VERSION ""

NS_ :

BS_:

BU_:
VAL_TABLE_ TM2B_FaultCode_A 57 "压缩机失速" 56 "压缩机 2 故障" 55 "压缩机故障" 51 "母线欠压" 50 "排气温度传感器故障" 49 "高压总回路接触器故障" 48 "BMS 和 TMS CAN 通讯异常" 47 "DCDC 供电故障" 42 "从机组 2 丢失" 40 "从机组 2 二级故障" 39 "从机组 2 一级故障" 38 "从机组 1 丢失" 36 "从机组 1 二级故障" 35 "从机组 1 一级故障" 34 "DCDC 故障" 33 "K2 继电器故障" 32 "高压预冲故障" 31 "PTC 通讯故障" 30 "水位低报警" 28 "ATS 水泵故障" 27 "水泵故障" 26 "压缩机 2 通讯故障" 25 "机组出水温度传感器" 24 "机组进水温度传感器" 23 "低压传感器" 22 "高压传感器" 21 "风扇故障" 19 "压缩机通讯故障" 3 "面板空调故障" 2 "PTC 故障" 1 "PTC 高级故障" 0 "无故障" ;
VAL_TABLE_ B2V_ST1_PantoChrgPosRelaySt 3 "Signal Invalid" 2 "Closed" 1 "Opened" 0 "Reserved" ;
VAL_TABLE_ B2V_ST1_PantoChrgNegRelaySt 3 "Signal Invalid" 2 "Closed" 1 "Opened" 0 "Reserved" ;
VAL_TABLE_ B2V_Fult2_ContiCurrOverLoad 3 "Level3-Most severe fault" 2 "Level 2-

More severe fault" 1 "Level 1-Light fault" 0 "Normal" ;
VAL_TABLE_ B2V_Fult2_ContiChrgCurrOverLoad 3 "Level3-Most severe fault" 2 "Level 2-

More severe fault" 1 "Level 1-Light fault" 0 "Normal" ;
VAL_TABLE_ B2V_Fult2_OverChrgCurrInTheChrg 1 "Fault" 0 "Norma" ;
VAL_TABLE_ B2V_Fult2_PanChrgNegRelOpEr 1 "Fault" 0 "Norma" ;
VAL_TABLE_ B2V_Fult2_PantoChrgNegRelWeldErr 1 "Fault" 0 "Norma" ;
VAL_TABLE_ B2V_Fult2_PantoChrgPosRelWeldErr 1 "Fault" 0 "Norma" ;
VAL_TABLE_ B2V_Fult2_DCChrgPos4RelayOpenErr 1 "Fault" 0 "Norma" ;
VAL_TABLE_ B2V_Fult2_DCChrgNeg3RelayWeldErr 1 "Fault" 0 "Norma" ;
VAL_TABLE_ B2V_Fult2_DCChrgNeg3RelayOpenErr 1 "Fault" 0 "Norma" ;
VAL_TABLE_ B2V_Fult2_DCChrgPos3RelayWeldErr 1 "Fault" 0 "Norma" ;
VAL_TABLE_ B2V_Fult2_DCChrgPos3RelayOpenErr 1 "Fault" 0 "Norma" ;
VAL_TABLE_ B2V_Fult2_DCChrgNeg2RelayWeldErr 1 "Fault" 0 "Norma" ;
VAL_TABLE_ B2V_Fult2_DCChrgNeg2RelayOpenErr 1 "Fault" 0 "Norma" ;
VAL_TABLE_ B2V_Fult2_DCChrgPos2RelayWeldErr 1 "Fault" 0 "Norma" ;
VAL_TABLE_ B2V_Fult2_DCChrgPos2RelayOpenErr 1 "Fault" 0 "Norma" ;
VAL_TABLE_ B2V_Fult2_DCChrgNeg1RelayWeldErr 1 "Fault" 0 "Norma" ;
VAL_TABLE_ B2V_Fult2_DCChrgNeg1RelayOpenErr 1 "Fault" 0 "Norma" ;
VAL_TABLE_ B2V_Fult2_DCChrgPos1RelayWeldErr 1 "Fault" 0 "Norma" ;
VAL_TABLE_ B2V_Fult2_DCChrgPos1RelayOpenErr 1 "Fault" 0 "Norma" ;
VAL_TABLE_ B2V_Fult2_MainNegRelayWeldErr 1 "Fault" 0 "Norma" ;
VAL_TABLE_ B2V_Fult2_MainNegRelayOpenErr 1 "Fault" 0 "Norma" ;
VAL_TABLE_ B2V_Fult2_MainPosRelayWeldErr 1 "Fault" 0 "Norma" ;
VAL_TABLE_ B2V_Fult2_MainPosRelayOpenErr 1 "Fault" 0 "Norma" ;
VAL_TABLE_ B2V_Fult2_InnerCommunicationErr 1 "Fault" 0 "Norma" ;
VAL_TABLE_ B2V_Fult2_AuxLoopPrechrgErr 1 "Fault" 0 "Norma" ;
VAL_TABLE_ B2V_Fult2_MainLoopPrechrgErr 1 "Fault" 0 "Norma" ;
VAL_TABLE_ B2V_Fult2_OverChrgCurrInTheDrive 3 "Level3-Most severe fault" 2 "Level 2-

More severe fault" 1 "Level 1-Light fault" 0 "Normal" ;
VAL_TABLE_ B2T_BMS_HVRelayST_A 3 "Invalid" 2 "Invalid" 1 "下高压" 0 "上高压" ;
VAL_TABLE_ B2T_ChgST_A 3 "Invalid" 2 "Invalid" 1 "Charging mode" 0 "Non-Charging mode" ;
VAL_TABLE_ B2T_RQ_HV_A 3 "Invalid" 2 "Invalid" 1 "HV Off Request" 0 "HV On Request" ;
VAL_TABLE_ B2T_RQ_SetMode_A 3 "Self-Loop Mode" 2 "Heat Mode" 1 "Cooling Mode" 0 "Shutdown Mode" ;
VAL_TABLE_ B2V_ISO_ALARM_STA 170 "无绝缘故障" 85 "有绝缘故障" ;
VAL_TABLE_ B2V_ISO_RUN_STA 170 "正常运行" 85 "绝缘功能关闭" ;
VAL_TABLE_ B2V_ISO_MSD1 1 "有故障" 0 "无故障" ;
VAL_TABLE_ B2V_ISO_MSD2 1 "有输入" 0 "无输入" ;
VAL_TABLE_ B2V_ISO_FAULT_DIR 2 "偏负母线故障" 1 "偏正母线故障" 0 "无故障" ;
VAL_TABLE_ V2B_CC2_1 1 "Connected" 0 "Not connected" ;
VAL_TABLE_ B2V_ST1_CoolingStatus 1 "cooling" 0 "not cooling" ;
VAL_TABLE_ B2V_ST1_HeatingStatus 1 "heating" 0 "not heat" ;
VAL_TABLE_ B2V_ST1_ChrgStatus 3 "Charge error" 2 "Charge Finished" 1 "Charging" 0 "not charging" ;
VAL_TABLE_ B2V_ST1_ChrgMode 3 "Other charging" 2 "AC charging" 1 "DC charging" 0 "Notcharging" ;
VAL_TABLE_ B2V_ST1_ACChrgConnectSt 1 "Connected" 0 "Not connected" ;
VAL_TABLE_ B2V_ST1_PantoChrgConnectSt 1 "Connected" 0 "Not connected" ;
VAL_TABLE_ B2V_ST1_DCChrgConnectSt 3 "Invalid" 2 "double gun connect" 1 "single gun connect" 0 "Not connected" ;
VAL_TABLE_ B2V_ST1_BMS_BalanceStatus 1 "Balancing" 0 "No Balancing" ;
VAL_TABLE_ B2V_ST1_BMS_HVStatus 3 "Fail to HV on" 2 "HV closed" 1 "Precharge or Precheck" 0 "HV open" ;
VAL_TABLE_ B2V_ST1_Aux3RelaySt 3 "Signal Invalid" 2 "Closed" 1 "Opened" 0 "Reserved" ;
VAL_TABLE_ B2V_ST1_Aux2RelaySt 3 "Signal Invalid" 2 "Closed" 1 "Opened" 0 "Reserved" ;
VAL_TABLE_ B2V_ST1_Aux1RelaySt 3 "Signal Invalid" 2 "Closed" 1 "Opened" 0 "Reserved" ;
VAL_TABLE_ B2V_ST1_ACChrgNegRelaySt 3 "Signal Invalid" 2 "Closed" 1 "Opened" 0 "Reserved" ;
VAL_TABLE_ B2V_ST1_ACChrgPosRelaySt 3 "Signal Invalid" 2 "Closed" 1 "Opened" 0 "Reserved" ;
VAL_TABLE_ B2V_ST1_PantoChrgNegRelaySt 3 "Signal Invalid" 2 "Closed" 1 "Opened" 0 "Reserved" ;
VAL_TABLE_ B2V_ST1_PantoChrgPosRelaySt 3 "Signal Invalid" 2 "Closed" 1 "Opened" 0 "Reserved" ;
VAL_TABLE_ B2V_ST1_HeatNegRelaySt 3 "Signal Invalid" 2 "Closed" 1 "Opened" 0 "Reserved" ;
VAL_TABLE_ B2V_ST1_HeatPosRelaySt 3 "Signal Invalid" 2 "Closed" 1 "Opened" 0 "Reserved" ;
VAL_TABLE_ B2V_ST1_DCChrgNeg2RelaySt 3 "Signal Invalid" 2 "Closed" 1 "Opened" 0 "Reserved" ;
VAL_TABLE_ B2V_ST1_DCChrgPos2RelaySt 3 "Signal Invalid" 2 "Closed" 1 "Opened" 0 "Reserved" ;
VAL_TABLE_ B2V_ST1_DCChrgNeg1RelaySt 3 "Signal Invalid" 2 "Closed" 1 "Opened" 0 "Reserved" ;
VAL_TABLE_ B2V_ST1_DCChrgPos1RelaySt 3 "Signal Invalid" 2 "Closed" 1 "Opened" 0 "Reserved" ;
VAL_TABLE_ B2V_ST1_PrechrgRelaySt 3 "Signal Invalid" 2 "Closed" 1 "Opened" 0 "Reserved" ;
VAL_TABLE_ B2V_ST1_MainNegRelaySt 3 "Signal Invalid" 2 "Closed" 1 "Opened" 0 "Reserved" ;
VAL_TABLE_ B2V_ST1_MainPosRelaySt 3 "Signal Invalid" 2 "Closed" 1 "Opened" 0 "Reserved" ;
VAL_TABLE_ B2V_Fult1_HVILFault 2 "Fault" 0 "Normal" ;
VAL_TABLE_ B2V_Fult1_BatSysNotMatch 2 "Fault" 0 "Normal" ;
VAL_TABLE_ B2V_Fult1_SOCChangeFast 2 "Fault" 0 "Normal" ;
VAL_TABLE_ B2V_Fult1_OverSOC 3 "Level 3 - Most severe fault" 2 "Level 2- More severe fault" 1 "Level 1-Light fault" 0 "Normal" ;
VAL_TABLE_ B2V_Fult1_OverChg 3 "Level 3 - Most severe fault" 2 "Level 2- More severe fault" 1 "Level 1-Light fault" 0 "Normal" ;
VAL_TABLE_ B2V_Fult1_UcellUniformity 3 "Level 3 - Most severe fault" 2 "Level 2- More severe fault" 1 "Level 1-Light fault" 0 "Normal" ;
VAL_TABLE_ B2V_Fult1_LowInsRes 3 "Level 3 - Most severe fault" 2 "Level 2- More severe fault" 1 "Level 1-Light fault" 0 "Normal" ;
VAL_TABLE_ B2V_Fult1_LowUcell 3 "Level 3 - Most severe fault" 2 "Level 2- More severe fault" 1 "Level 1-Light fault" 0 "Normal" ;
VAL_TABLE_ B2V_Fult1_OverUcell 3 "Level 3 - Most severe fault" 2 "Level 2- More severe fault" 1 "Level 1-Light fault" 0 "Normal" ;
VAL_TABLE_ B2V_Fult1_LowSOC 3 "Level 3 - Most severe fault" 2 "Level 2- More severe fault" 1 "Level 1-Light fault" 0 "Normal" ;
VAL_TABLE_ B2V_Fult1_PackLowHVolt 3 "Level 3 - Most severe fault" 2 "Level 2- More severe fault" 1 "Level 1-Light fault" 0 "Normal" ;
VAL_TABLE_ B2V_Fult1_PackOverHVolt 3 "Level 3 - Most severe fault" 2 "Level 2- More severe fault" 1 "Level 1-Light fault" 0 "Normal" ;
VAL_TABLE_ B2V_Fult1_OverTemp 3 "Level 3 - Most severe fault" 2 "Level 2- More severe fault" 1 "Level 1-Light fault" 0 "Normal" ;
VAL_TABLE_ B2V_Fult1_DelTemp 3 "Level 3 - Most severe fault" 2 "Level 2- More severe fault" 1 "Level 1-Light fault" 0 "Normal" ;
VAL_TABLE_ B2V_SN_FrameNo 3 "Frame4" 2 "Frame3" 1 "Frame2" 0 "Frame1" ;
VAL_TABLE_ B2V_SN_SysCode_B6_12_18_24 90 "Z" 89 "Y" 88 "X" 87 "W" 86 "V" 85 "U" 84 "T" 83 "S" 82 "R" 81 "Q" 80 "P" 79 "O" 78 "N" 77 "M" 76 "L" 75 "K" 74 "J" 73 "I" 72 "H" 71 "G" 70 "F" 69 "E" 68 "D" 67 "C" 66 "B" 65 "A" 57 "9" 56 "8" 55 "7" 54 "6" 53 "5" 52 "4" 51 "3" 50 "2" 49 "1" 48 "0" ;
VAL_TABLE_ B2V_SN_SysCode_B5_11_17_23 90 "Z" 89 "Y" 88 "X" 87 "W" 86 "V" 85 "U" 84 "T" 83 "S" 82 "R" 81 "Q" 80 "P" 79 "O" 78 "N" 77 "M" 76 "L" 75 "K" 74 "J" 73 "I" 72 "H" 71 "G" 70 "F" 69 "E" 68 "D" 67 "C" 66 "B" 65 "A" 57 "9" 56 "8" 55 "7" 54 "6" 53 "5" 52 "4" 51 "3" 50 "2" 49 "1" 48 "0" ;
VAL_TABLE_ B2V_SN_SysCode_B4_10_16_22 90 "Z" 89 "Y" 88 "X" 87 "W" 86 "V" 85 "U" 84 "T" 83 "S" 82 "R" 81 "Q" 80 "P" 79 "O" 78 "N" 77 "M" 76 "L" 75 "K" 74 "J" 73 "I" 72 "H" 71 "G" 70 "F" 69 "E" 68 "D" 67 "C" 66 "B" 65 "A" 57 "9" 56 "8" 55 "7" 54 "6" 53 "5" 52 "4" 51 "3" 50 "2" 49 "1" 48 "0" ;
VAL_TABLE_ B2V_SN_SysCode_B3_9_15_21 90 "Z" 89 "Y" 88 "X" 87 "W" 86 "V" 85 "U" 84 "T" 83 "S" 82 "R" 81 "Q" 80 "P" 79 "O" 78 "N" 77 "M" 76 "L" 75 "K" 74 "J" 73 "I" 72 "H" 71 "G" 70 "F" 69 "E" 68 "D" 67 "C" 66 "B" 65 "A" 57 "9" 56 "8" 55 "7" 54 "6" 53 "5" 52 "4" 51 "3" 50 "2" 49 "1" 48 "0" ;
VAL_TABLE_ B2V_SN_SysCode_B2_8_14_20 90 "Z" 89 "Y" 88 "X" 87 "W" 86 "V" 85 "U" 84 "T" 83 "S" 82 "R" 81 "Q" 80 "P" 79 "O" 78 "N" 77 "M" 76 "L" 75 "K" 74 "J" 73 "I" 72 "H" 71 "G" 70 "F" 69 "E" 68 "D" 67 "C" 66 "B" 65 "A" 57 "9" 56 "8" 55 "7" 54 "6" 53 "5" 52 "4" 51 "3" 50 "2" 49 "1" 48 "0" ;
VAL_TABLE_ B2V_SN_SysCode_B1_7_13_19 90 "Z" 89 "Y" 88 "X" 87 "W" 86 "V" 85 "U" 84 "T" 83 "S" 82 "R" 81 "Q" 80 "P" 79 "O" 78 "N" 77 "M" 76 "L" 75 "K" 74 "J" 73 "I" 72 "H" 71 "G" 70 "F" 69 "E" 68 "D" 67 "C" 66 "B" 65 "A" 57 "9" 56 "8" 55 "7" 54 "6" 53 "5" 52 "4" 51 "3" 50 "2" 49 "1" 48 "0" ;
VAL_TABLE_ B2V_RQ_VIN 1 "Request VIN" 0 "Not Request VIN" ;
VAL_TABLE_ V2B_CMD_MainNegRelayFlt 3 "Signal Invalid" 2 "Opened Fault" 1 "Weld" 0 "Normal" ;
VAL_TABLE_ V2B_CMD_Aux4RelayFlt 3 "Signal Invalid" 2 "Opened Fault" 1 "Weld" 0 "Normal" ;
VAL_TABLE_ V2B_CMD_Aux3RelayFlt 3 "Signal Invalid" 2 "Opened Fault" 1 "Weld" 0 "Normal" ;
VAL_TABLE_ V2B_CMD_Aux2RelayFlt 3 "Signal Invalid" 2 "Opened Fault" 1 "Weld" 0 "Normal" ;
VAL_TABLE_ V2B_CMD_Aux1RelayFlt 3 "Signal Invalid" 2 "Opened Fault" 1 "Weld" 0 "Normal" ;
VAL_TABLE_ V2B_CMD_HeatNegRelayFlt 3 "Signal Invalid" 2 "Opened Fault" 1 "Weld" 0 "Normal" ;
VAL_TABLE_ V2B_CMD_HeatPosRelayFlt 3 "Signal Invalid" 2 "Opened Fault" 1 "Weld" 0 "Normal" ;
VAL_TABLE_ V2B_CMD_ChrgPosRelayFlt 3 "Signal Invalid" 2 "Opened Fault" 1 "Weld" 0 "Normal" ;
VAL_TABLE_ V2B_CMD_MainPosRelayFlt 3 "Signal Invalid" 2 "Opened Fault" 1 "Weld" 0 "Normal" ;
VAL_TABLE_ V2B_CMD_Aux3RelayST 3 "Invalid" 2 "Closed" 1 "Opened" 0 "Reserved" ;
VAL_TABLE_ V2B_CMD_Aux2RelayST 3 "Invalid" 2 "Closed" 1 "Opened" 0 "Reserved" ;
VAL_TABLE_ V2B_CMD_Aux1RelayST 3 "Invalid" 2 "Closed" 1 "Opened" 0 "Reserved" ;
VAL_TABLE_ V2B_CMD_HeatPosRelayST 3 "Invalid" 2 "Closed" 1 "Opened" 0 "Reserved" ;
VAL_TABLE_ V2B_CMD_MainNegRelayST 3 "Invalid" 2 "Closed" 1 "Opened" 0 "Reserved" ;
VAL_TABLE_ V2B_CMD_Aux4RelayST 3 "Invalid" 2 "Closed" 1 "Opened" 0 "Reserved" ;
VAL_TABLE_ V2B_CMD_HeatNegRelayST 3 "Invalid" 2 "Closed" 1 "Opened" 0 "Reserved" ;
VAL_TABLE_ V2B_CMD_ChrgPosRelayST 3 "Invalid" 2 "Closed" 1 "Opened" 0 "Reserved" ;
VAL_TABLE_ V2B_CMD_MainPosRelayST 3 "Invalid" 2 "Closed" 1 "Opened" 0 "Reserved" ;
VAL_TABLE_ V2B_CMD_Aux3OnOff 3 "Invalid" 2 "PowerOff" 1 "PowerOn" 0 "Reserved" ;
VAL_TABLE_ V2B_CMD_Aux2OnOff 3 "Invalid" 2 "PowerOff" 1 "PowerOn" 0 "Reserved" ;
VAL_TABLE_ V2B_CMD_Aux1OnOff 3 "Invalid" 2 "PowerOff" 1 "PowerOn" 0 "Reserved" ;
VAL_TABLE_ V2B_CMD_HV_OnOff 3 "Invalid" 2 "PowerOff" 1 "PowerOn" 0 "Reserved" ;
VAL_TABLE_ V4B_MainPos 1 "Close" 0 "Open" ;
VAL_TABLE_ V3B_KeyonRun 1 "Stick" 0 "Normal" ;
VAL_TABLE_ V3B_Keyon 1 "Stick" 0 "Normal" ;
VAL_TABLE_ V2B_AUXPreRelayFlt 1 "Stick" 0 "Normal" ;
VAL_TABLE_ V2B_AUXRelayFlt 1 "Stick" 0 "Normal" ;
VAL_TABLE_ V2B_MainAuxPreRelayFlt 1 "Stick" 0 "Normal" ;
VAL_TABLE_ V2B_MainAUXRelayFlt 1 "Stick" 0 "Normal" ;
VAL_TABLE_ V2B_AUXPreRelayST 1 "Stick" 0 "Normal" ;
VAL_TABLE_ V2B_AUXRelayST 1 "Stick" 0 "Normal" ;
VAL_TABLE_ V2B_MainAuxPreRelayST 1 "Stick" 0 "Normal" ;
VAL_TABLE_ V2B_MainAuxRelayST 1 "Stick" 0 "Normal" ;
VAL_TABLE_ V2B_MainPos6RelayFlt 1 "Stick" 0 "Normal" ;
VAL_TABLE_ V2B_MainPos5RelayFlt 1 "Stick" 0 "Normal" ;
VAL_TABLE_ V2B_MainPos4RelayFlt 1 "Stick" 0 "Normal" ;
VAL_TABLE_ V2B_MainPos3RelayFlt 1 "Stick" 0 "Normal" ;
VAL_TABLE_ V2B_MainPos2RelayFlt 1 "Stick" 0 "Normal" ;
VAL_TABLE_ V2B_MainPos1RelayFlt 1 "Stick" 0 "Normal" ;
VAL_TABLE_ V2B_MainPosRelayFlt1 1 "Stick" 0 "Normal" ;
VAL_TABLE_ V2B_HeatNegRelayFlt1 1 "Stick" 0 "Normal" ;
VAL_TABLE_ V2B_HeatPosRelayFlt1 1 "Stick" 0 "Normal" ;
VAL_TABLE_ V2B_ChgNeg4RelayFlt 1 "Stick" 0 "Normal" ;
VAL_TABLE_ V2B_ChgPos4RelayFlt 1 "Stick" 0 "Normal" ;
VAL_TABLE_ V2B_ChgNeg3RelayFlt 1 "Stick" 0 "Normal" ;
VAL_TABLE_ V2B_ChgPos3RelayFlt 1 "Stick" 0 "Normal" ;
VAL_TABLE_ V2B_ChgNeg2RelayFlt 1 "Stick" 0 "Normal" ;
VAL_TABLE_ V2B_ChgPos2RelayFlt 1 "Stick" 0 "Normal" ;
VAL_TABLE_ V2B_ChgNeg1RelayFlt 1 "Stick" 0 "Normal" ;
VAL_TABLE_ V2B_ChgPos1RelayFlt 1 "Stick" 0 "Normal" ;
VAL_TABLE_ V2B_MainNegRelayFlt1 1 "Stick" 0 "Normal" ;
VAL_TABLE_ V7B_MainPos 1 "Close" 0 "Open" ;
VAL_TABLE_ V6B_MainPos 1 "Close" 0 "Open" ;
VAL_TABLE_ V5B_MainPos 1 "Close" 0 "Open" ;
VAL_TABLE_ V3B_MainPos 1 "Close" 0 "Open" ;
VAL_TABLE_ V2B_MainPos 1 "Close" 0 "Open" ;
VAL_TABLE_ V2B_HeatNegRelaySt 1 "Close" 0 "Open" ;
VAL_TABLE_ V2B_HeatPosRelaySt 1 "Close" 0 "Open" ;
VAL_TABLE_ V2B_DCChrgNeg4RelaySt 1 "Close" 0 "Open" ;
VAL_TABLE_ V2B_DCChrgPos4RelaySt 1 "Close" 0 "Open" ;
VAL_TABLE_ V2B_DCChrgNeg3RelaySt 1 "Close" 0 "Open" ;
VAL_TABLE_ V2B_DCChrgPos3RelaySt 1 "Close" 0 "Open" ;
VAL_TABLE_ V2B_DCChrgNeg2RelaySt 1 "Close" 0 "Open" ;
VAL_TABLE_ V2B_DCChrgPos2RelaySt 1 "Close" 0 "Open" ;
VAL_TABLE_ V2B_DCChrgNeg1RelaySt 1 "Close" 0 "Open" ;
VAL_TABLE_ V2B_DCChrgPos1RelaySt 1 "Close" 0 "Open" ;
VAL_TABLE_ V2B_MainNegRelaySt 1 "Close" 0 "Open" ;
VAL_TABLE_ TM2B_FaultLevel_A 0 "Normal" 3 "Level 3 Fault" 2 "Level 2 Fault" 1 "Level 1 Fault" ;
VAL_TABLE_ T2B_TMS_HVRelayST_A 1 "Close" 0 "Open" ;
VAL_TABLE_ T2B_WorkStatus_A 3 "Self-Loop Mode" 2 "Heat

Mode" 1 "Cooling Mode" 0 "Shutdown Mode" ;
VAL_TABLE_ B2V_InsForbidCMD 1 "allow

insulation detection" 0 "forbid insulation detection" ;
VAL_TABLE_ B2V_MainPosRelayCMD 1 "require contactor

close" 0 "require contactor open" ;
VAL_TABLE_ B2V_HeatNegRelayCMD 1 "require contactor

close" 0 "require contactor open" ;
VAL_TABLE_ B2V_HeatPosRelayCMD 1 "require contactor

close" 0 "require contactor open" ;
VAL_TABLE_ B2VChrgRelay3CMD 1 "require contactor

close" 0 "require contactor open" ;
VAL_TABLE_ B2VChrgRelay2CMD 1 "require contactor

close" 0 "require contactor open" ;
VAL_TABLE_ B2VChrgRelay1CMD 1 "require contactor

close" 0 "require contactor open" ;
VAL_TABLE_ B2V_ChrgRelayCMD 1 "require contactor

close" 0 "require contactor open" ;
VAL_TABLE_ B2V_BI1_BattManufacture 7 "Others" 6 "SUNWODA" 5 "GUOXUAN HIGH_TECH" 4 "LG" 3 "SAMSUN" 2 "MGL" 1 "Li Shen" 0 "CATL" ;
VAL_TABLE_ B2V_BI1_BattType 14 "其他车载储能装置" 13 "燃

料电池 Fuel battery" 12 "Reserved" 11 "Reserved" 10 "Reserved" 9 "Reserved" 8 "超级电容Super-capaciyor" 7 "钛酸锂电池" 6 "聚合物锂离子电池" 5 "三元材料电池 NCM" 4 "钴酸锂电池" 3 "锰酸锂电池" 2 "磷酸铁锂电池LEP" 1 "镍氢电池NIMH Battery" 0 "铅酸电池Lead-acid battery" ;
VAL_TABLE_ B2V_S_ChargeControl 2 "Fault, Stop to charge" 1 "Normal Stop to charge" 0 "Start to charge" ;
VAL_TABLE_ B2V_ST6_MinUcell_CSCNo 18 "CSC18" 17 "CSC17" 16 "CSC16" 15 "CSC15" 14 "CSC14" 13 "CSC13" 12 "CSC12" 11 "CSC11" 10 "CSC10" 9 "CSC9" 8 "CSC8" 7 "CSC7" 6 "CSC6" 5 "CSC5" 4 "CSC4" 3 "CSC3" 2 "CSC2" 1 "CSC1" ;
VAL_TABLE_ B2V_ST6_MaxUcell_CSCNo 18 "CSC18" 17 "CSC17" 16 "CSC16" 15 "CSC15" 14 "CSC14" 13 "CSC13" 12 "CSC12" 11 "CSC11" 10 "CSC10" 9 "CSC9" 8 "CSC8" 7 "CSC7" 6 "CSC6" 5 "CSC5" 4 "CSC4" 3 "CSC3" 2 "CSC2" 1 "CSC1" ;
VAL_TABLE_ B2V_ST4_MinTemp_CSCNo 18 "CSC18" 17 "CSC17" 16 "CSC16" 15 "CSC15" 14 "CSC14" 13 "CSC13" 12 "CSC12" 11 "CSC11" 10 "CSC10" 9 "CSC9" 8 "CSC8" 7 "CSC7" 6 "CSC6" 5 "CSC5" 4 "CSC4" 3 "CSC3" 2 "CSC2" 1 "CSC1" ;
VAL_TABLE_ B2V_ST4_MaxTemp_CSCNo 18 "CSC18" 17 "CSC17" 16 "CSC16" 15 "CSC15" 14 "CSC14" 13 "CSC13" 12 "CSC12" 11 "CSC11" 10 "CSC10" 9 "CSC9" 8 "CSC8" 7 "CSC7" 6 "CSC6" 5 "CSC5" 4 "CSC4" 3 "CSC3" 2 "CSC2" 1 "CSC1" ;
VAL_TABLE_ B2V_ST2_RqHVPoerOff 3 "Signal Invalid" 2 "not

require power off" 1 "require power off" 0 "Signal Invalid" ;
VAL_TABLE_ B2V_ST2_FaultLevel 3 "Level3-Most severe fault" 2 "Level 2-

More severe fault" 1 "Level 1-Light fault" 0 "Normal" ;
VAL_TABLE_ B2V_Fult2_DCChrgPos1RelayWeldErr 1 "Fault" 0 "Norma" ;
VAL_TABLE_ B2V_Fult2_ACANLost 1 "Fault" 0 "Normal" ;
VAL_TABLE_ B2V_Fult2_ContiDischrgCurrLoad 3 "Level3-Most severe fault" 2 "Level 2-

More severe fault" 1 "Level 1-Light fault" 0 "Normal" ;
VAL_TABLE_ B2V_Fult2_ContiChrgCurrOverLoad 3 "Level3-Most severe fault" 2 "Level 2-

More severe fault" 1 "Level 1-Light fault" 0 "Normal" ;
VAL_TABLE_ B2V_Fult2_ChrgNTCTempOver 3 "Level3-Most severe fault" 2 "Level 2-

More severe fault" 1 "Level 1-Light fault" 0 "Normal" ;
VAL_TABLE_ B2V_Fult2_OverChrgCurrInTheDrive 3 "Level3-Most severe fault" 2 "Level 2-

More severe fault" 1 "Level 1-Light fault" 0 "Normal" ;
VAL_TABLE_ B2V_Fult2_OverDischrgCurr 3 "Level3-Most severe fault" 2 "Level 2-

More severe fault" 1 "Level 1-Light fault" 0 "Normal" ;
VAL_TABLE_ B2V_Fult2_SOCDifferErr 1 "Fault" 0 "Norma" ;
VAL_TABLE_ B2V_Fult2_FireDetectorErr 1 "Fault" 0 "Norma" ;
VAL_TABLE_ B2V_Fult2_ELockErr 1 "Fault" 0 "Norma" ;
VAL_TABLE_ B2V_Fult2_ChrgNTCErr 1 "Fault" 0 "Norma" ;
VAL_TABLE_ B2V_Fult2_OverChrgCurrInTheChrg 1 "Fault" 0 "Norma" ;
VAL_TABLE_ B2V_Fult2_OverDischrCurrWhCh 1 "Fault" 0 "Norma" ;
VAL_TABLE_ B2V_Fult2_ChrgConnectErr 1 "Fault" 0 "Norma" ;
VAL_TABLE_ B2V_Fult2_PantoChrgNegRelWeldEr 1 "Fault" 0 "Norma" ;
VAL_TABLE_ B2V_Fult2_PantoChrgNegRelOpenEr 1 "Fault" 0 "Norma" ;
VAL_TABLE_ B2V_Fult2_PantoChrgPosRelWeldErr 1 "Fault" 0 "Norma" ;
VAL_TABLE_ B2V_Fult2_DCChrgPos4RelayOpenErr 1 "Fault" 0 "Norma" ;
VAL_TABLE_ B2V_Fult2_DCChrgNeg3RelayWeldErr 1 "Fault" 0 "Norma" ;
VAL_TABLE_ B2V_Fult2_DCChrgNeg3RelayOpenErr 1 "Fault" 0 "Norma" ;
VAL_TABLE_ B2V_Fult2_DCChrgPos3RelayWeldErr 1 "Fault" 0 "Norma" ;
VAL_TABLE_ B2V_Fult2_DCChrgPos3RelayOpenErr 1 "Fault" 0 "Norma" ;
VAL_TABLE_ B2V_Fult2_DCChrgNeg2RelayWeldErr 1 "Fault" 0 "Norma" ;
VAL_TABLE_ B2V_Fult2_DCChrgNeg2RelayOpenErr 1 "Fault" 0 "Norma" ;
VAL_TABLE_ B2V_Fult2_DCChrgPos2RelayWeldErr 1 "Fault" 0 "Norma" ;
VAL_TABLE_ B2V_Fult2_DCChrgPos2RelayOpenErr 1 "Fault" 0 "Norma" ;
VAL_TABLE_ B2V_Fult2_DCChrgNeg1RelayWeldErr 1 "Fault" 0 "Norma" ;
VAL_TABLE_ B2V_Fult2_DCChrgNeg1RelayOpenErr 1 "Fault" 0 "Norma" ;
VAL_TABLE_ B2V_Fult2_DCChrgPos1RelayOpenErr 1 "Fault" 0 "Norma" ;
VAL_TABLE_ B2V_Fult2_MainNegRelayWeldErr 1 "Fault" 0 "Norma" ;
VAL_TABLE_ B2V_Fult2_MainNegRelayOpenErr 1 "Fault" 0 "Norma" ;
VAL_TABLE_ B2V_Fult2_MainPosRelayWeldErr 1 "Fault" 0 "Norma" ;
VAL_TABLE_ B2V_Fult2_MainPosRelayOpenErr 1 "Fault" 0 "Norma" ;
VAL_TABLE_ B2V_Fult2_HeatRelayWeldErr 1 "Fault" 0 "Norma" ;
VAL_TABLE_ B2V_Fult2_HeatRelayOpenErr 1 "Fault" 0 "Norma" ;
VAL_TABLE_ B2V_Fult2_BranchBreakErr 1 "Fault" 0 "Norma" ;
VAL_TABLE_ B2V_Fult2_InnerCommunicationErr 1 "Fault" 0 "Norma" ;
VAL_TABLE_ B2V_Fult2_DCDCErr 1 "Fault" 0 "Norma" ;
VAL_TABLE_ B2V_Fult2_ChrgInsLowErr 1 "Fault" 0 "Norma" ;
VAL_TABLE_ B2V_Fult2_AuxLoopPrechrgErr 1 "Fault" 0 "Norma" ;
VAL_TABLE_ B2V_Fult2_MainLoopPrechrgErr 1 "Fault" 0 "Norma" ;
VAL_TABLE_ B2V_Fult2_PackSelfProtect 1 "Fault" 0 "Norma" ;
VAL_TABLE_ B2V_Fult2_HeatungFilmErr 1 "Fault" 0 "Norma" ;
VAL_TABLE_ B2V_Fult2_TMSErr 1 "Fault" 0 "Norma" ;
VAL_TABLE_ B2V_Fult2_PowerSupplyErr 1 "Fault" 0 "Norma" ;
VAL_TABLE_ B2V_Fult2_CurrSensorErr 1 "Fault" 0 "Norma" ;
VAL_TABLE_ B2V_Fult2_PackFireWarning 1 "Fault" 0 "Norma" ;
VAL_TABLE_ B2V_Fult2_CellLowTemp 1 "Fault" 0 "Norma" ;
VAL_TABLE_ B2V_Fult2_CellOverDischrg 1 "Fault" 0 "Norma" ;
VAL_TABLE_ B2V_BI1_BattManufacture 7 "Others" 6 "SUNWODA" 5 "GUOXUAN HIGH_TECH" 4 "LG" 3 "SAMSUN" 2 "MGL" 1 "Li Shen" 0 "CATL" ;
VAL_TABLE_ B2V_BI1_CoolType 3 "Water cooling" 2 "Fan cooling" 1 "Natural cooling" 0 "Other cooling mode" ;
VAL_TABLE_ B2V_BI1_BattType 14 "其他车载储能装置" 13 "燃

料电池 Fuel battery" 12 "Reserved" 11 "Reserved" 10 "Reserved" 9 "Reserved" 8 "超级电容Super-capaciyor" 7 "钛酸锂电池" 6 "聚合物锂离子电池" 5 "三元材料电池 NCM" 4 "钴酸锂电池" 3 "锰酸锂电池" 2 "磷酸铁锂电池LEP" 1 "镍氢电池NIMH Battery" 0 "铅酸电池Lead-acid battery" ;
VAL_TABLE_ V2B_VIN_B7_14 90 "Z" 89 "Y" 88 "X" 87 "W" 86 "V" 85 "U" 84 "T" 83 "S" 82 "R" 81 "Q" 80 "P" 79 "O" 78 "N" 77 "M" 76 "L" 75 "K" 74 "J" 73 "I" 72 "H" 71 "G" 70 "F" 69 "E" 68 "D" 67 "C" 66 "B" 65 "A" 57 "9" 56 "8" 55 "7" 54 "6" 53 "5" 52 "4" 51 "3" 50 "2" 49 "1" 48 "0" ;
VAL_TABLE_ V2B_VIN_B6_13 90 "Z" 89 "Y" 88 "X" 87 "W" 86 "V" 85 "U" 84 "T" 83 "S" 82 "R" 81 "Q" 80 "P" 79 "O" 78 "N" 77 "M" 76 "L" 75 "K" 74 "J" 73 "I" 72 "H" 71 "G" 70 "F" 69 "E" 68 "D" 67 "C" 66 "B" 65 "A" 57 "9" 56 "8" 55 "7" 54 "6" 53 "5" 52 "4" 51 "3" 50 "2" 49 "1" 48 "0" ;
VAL_TABLE_ V2B_VIN_B5_12 90 "Z" 89 "Y" 88 "X" 87 "W" 86 "V" 85 "U" 84 "T" 83 "S" 82 "R" 81 "Q" 80 "P" 79 "O" 78 "N" 77 "M" 76 "L" 75 "K" 74 "J" 73 "I" 72 "H" 71 "G" 70 "F" 69 "E" 68 "D" 67 "C" 66 "B" 65 "A" 57 "9" 56 "8" 55 "7" 54 "6" 53 "5" 52 "4" 51 "3" 50 "2" 49 "1" 48 "0" ;
VAL_TABLE_ V2B_VIN_B4_11 90 "Z" 89 "Y" 88 "X" 87 "W" 86 "V" 85 "U" 84 "T" 83 "S" 82 "R" 81 "Q" 80 "P" 79 "O" 78 "N" 77 "M" 76 "L" 75 "K" 74 "J" 73 "I" 72 "H" 71 "G" 70 "F" 69 "E" 68 "D" 67 "C" 66 "B" 65 "A" 57 "9" 56 "8" 55 "7" 54 "6" 53 "5" 52 "4" 51 "3" 50 "2" 49 "1" 48 "0" ;
VAL_TABLE_ V2B_VIN_B3_10_17 90 "Z" 89 "Y" 88 "X" 87 "W" 86 "V" 85 "U" 84 "T" 83 "S" 82 "R" 81 "Q" 80 "P" 79 "O" 78 "N" 77 "M" 76 "L" 75 "K" 74 "J" 73 "I" 72 "H" 71 "G" 70 "F" 69 "E" 68 "D" 67 "C" 66 "B" 65 "A" 57 "9" 56 "8" 55 "7" 54 "6" 53 "5" 52 "4" 51 "3" 50 "2" 49 "1" 48 "0" ;
VAL_TABLE_ V2B_VIN_B2_9_16 90 "Z" 89 "Y" 88 "X" 87 "W" 86 "V" 85 "U" 84 "T" 83 "S" 82 "R" 81 "Q" 80 "P" 79 "O" 78 "N" 77 "M" 76 "L" 75 "K" 74 "J" 73 "I" 72 "H" 71 "G" 70 "F" 69 "E" 68 "D" 67 "C" 66 "B" 65 "A" 57 "9" 56 "8" 55 "7" 54 "6" 53 "5" 52 "4" 51 "3" 50 "2" 49 "1" 48 "0" ;
VAL_TABLE_ V2B_VIN_B1_8_15 90 "Z" 89 "Y" 88 "X" 87 "W" 86 "V" 85 "U" 84 "T" 83 "S" 82 "R" 81 "Q" 80 "P" 79 "O" 78 "N" 77 "M" 76 "L" 75 "K" 74 "J" 73 "I" 72 "H" 71 "G" 70 "F" 69 "E" 68 "D" 67 "C" 66 "B" 65 "A" 57 "9" 56 "8" 55 "7" 54 "6" 53 "5" 52 "4" 51 "3" 50 "2" 49 "1" 48 "0" ;
VAL_TABLE_ ISO_FaultLevel 3 "Level3-Most severe fault" 2 "Level 2-

More severe fault" 1 "Level 1-Light fault" 0 "Normal" ;
VAL_TABLE_ ISOWorkStatus 3 "equipment failure" 2 "stop work" 1 "working" 0 "Selfcheck" ;

BO_ 468 PDI1: 1 Vector__XXX
 SG_ X03 : 2|1@1- (1,0) [0|0] "" Vector__XXX
 SG_ X02 : 1|1@1- (1,0) [0|0] "" Vector__XXX

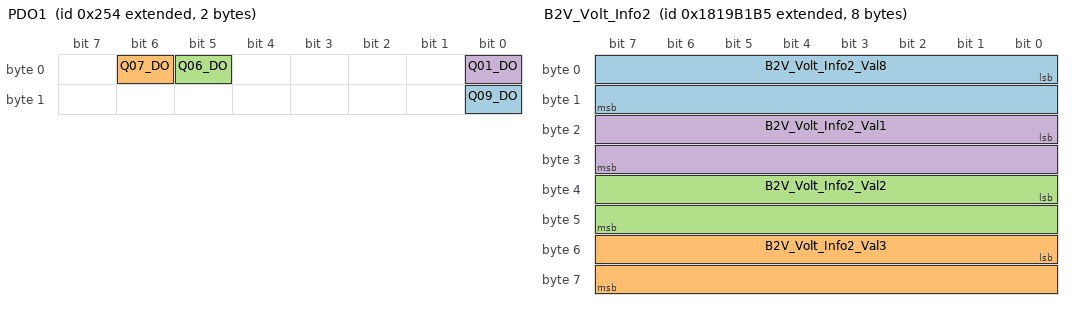
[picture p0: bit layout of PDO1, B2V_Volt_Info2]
BO_ 2147484244 PDO1: 2 Vector__XXX
 SG_ Q09_DO : 8|1@1- (1,0) [0|0] "" Vector__XXX
 SG_ Q07_DO : 6|1@1- (1,0) [0|0] "" Vector__XXX
 SG_ Q06_DO : 5|1@1- (1,0) [0|0] "" Vector__XXX
 SG_ Q01_DO : 0|1@1- (1,0) [0|0] "" Vector__XXX

BO_ 2585788163 V2B_ISO_SET: 6 Vector__XXX
 SG_ V2B_ISO_SET_RESERVED : 40|24@1- (1,0) [-8388608|8388607] "" Vector__XXX
 SG_ V2B_ISO_SET_CHEK_T : 8|8@1- (1,0) [0|0] "" Vector__XXX
 SG_ V2B_ISO_SET_CHEK_S : 0|8@1- (1,0) [0|0] "" Vector__XXX
 SG_ V2B_ISO_SET_CHEK_INSTRU : 32|8@1+ (1,0) [0|255] "" Vector__XXX
 SG_ V2B_ISO_SET_CHEK_B : 24|8@1- (1,0) [0|0] "" Vector__XXX
 SG_ V2B_ISO_SET_CHEK_A : 16|8@1- (1,0) [0|0] "" Vector__XXX

BO_ 2551820725 B2V_Volt_Info2: 8 Vector__XXX
 SG_ B2V_Volt_Info2_Val8 : 0|16@1- (0.1,0) [-1000|1000] "V" Vector__XXX
 SG_ B2V_Volt_Info2_Val3 : 48|16@1- (0.1,0) [-1000|1000] "V" Vector__XXX
 SG_ B2V_Volt_Info2_Val2 : 32|16@1- (0.1,0) [-1000|1000] "V" Vector__XXX
 SG_ B2V_Volt_Info2_Val1 : 16|16@1- (0.1,0) [-1000|1000] "V" Vector__XXX

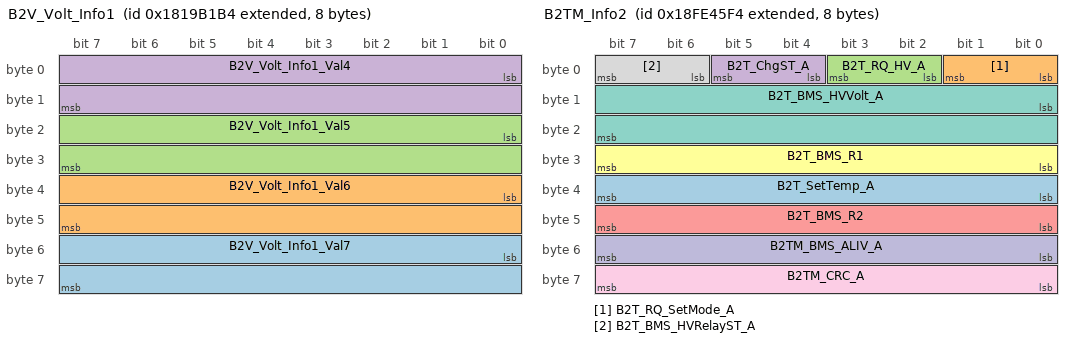
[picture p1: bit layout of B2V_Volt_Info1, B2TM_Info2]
BO_ 2551820724 B2V_Volt_Info1: 8 Vector__XXX
 SG_ B2V_Volt_Info1_Val7 : 48|16@1- (0.1,0) [-1000|1000] "V" Vector__XXX
 SG_ B2V_Volt_Info1_Val6 : 32|16@1- (0.1,0) [-1000|1000] "V" Vector__XXX
 SG_ B2V_Volt_Info1_Val5 : 16|16@1- (0.1,0) [-1000|1000] "V" Vector__XXX
 SG_ B2V_Volt_Info1_Val4 : 0|16@1- (0.1,0) [-1000|1000] "V" Vector__XXX

BO_ 2566800884 B2TM_Info2: 8 Vector__XXX
 SG_ B2T_SetTemp_A : 32|8@1- (1,-40) [-40|215] "℃" Vector__XXX
 SG_ B2T_RQ_SetMode_A : 0|2@1+ (1,0) [0|3] "" Vector__XXX
 SG_ B2T_RQ_HV_A : 2|2@1+ (1,0) [0|3] "" Vector__XXX
 SG_ B2T_ChgST_A : 4|2@1+ (1,0) [0|3] "" Vector__XXX
 SG_ B2T_BMS_R2 : 40|8@1+ (1,0) [0|0] "" Vector__XXX
 SG_ B2T_BMS_R1 : 24|8@1+ (1,0) [0|0] "" Vector__XXX
 SG_ B2T_BMS_HVVolt_A : 8|16@1+ (1,0) [0|65535] "" Vector__XXX
 SG_ B2T_BMS_HVRelayST_A : 6|2@1+ (1,0) [0|3] "" Vector__XXX
 SG_ B2TM_CRC_A : 56|8@1+ (1,0) [0|0] "" Vector__XXX
 SG_ B2TM_BMS_ALIV_A : 48|8@1+ (1,0) [0|0] "" Vector__XXX

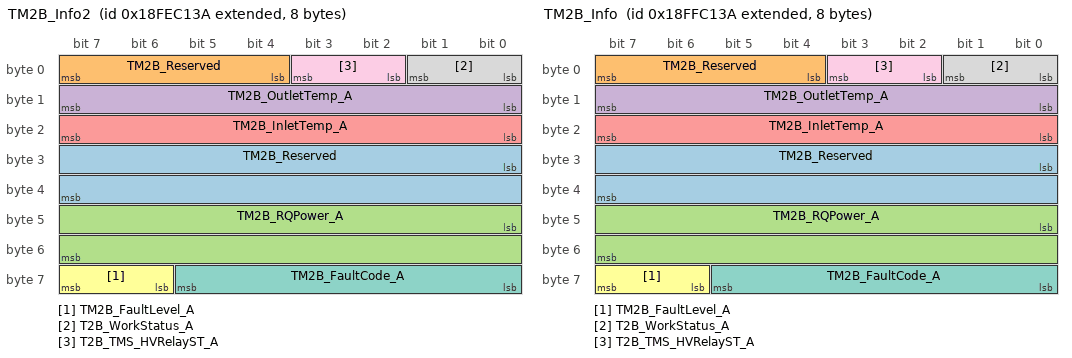
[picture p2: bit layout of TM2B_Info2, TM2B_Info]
BO_ 2566832442 TM2B_Info2: 8 Vector__XXX
 SG_ TM2B_Reserved : 24|16@1+ (1,0) [0|65535] "" Vector__XXX
 SG_ TM2B_Reserved : 4|4@1+ (1,0) [0|15] "" Vector__XXX
 SG_ TM2B_RQPower_A : 40|16@1+ (0.1,0) [0|6553.5] "Kw" Vector__XXX
 SG_ TM2B_OutletTemp_A : 8|8@1- (1,-40) [0|0] "℃" Vector__XXX
 SG_ TM2B_InletTemp_A : 16|8@1- (1,-40) [0|0] "℃" Vector__XXX
 SG_ TM2B_FaultLevel_A : 62|2@1+ (1,0) [0|3] "" Vector__XXX
 SG_ TM2B_FaultCode_A : 56|6@1+ (1,0) [0|0] "" Vector__XXX
 SG_ T2B_WorkStatus_A : 0|2@1+ (1,0) [0|0] "" Vector__XXX
 SG_ T2B_TMS_HVRelayST_A : 2|2@1+ (1,0) [0|3] "" Vector__XXX

BO_ 2566897978 TM2B_Info: 8 Vector__XXX
 SG_ TM2B_Reserved : 24|16@1+ (1,0) [0|65535] "" Vector__XXX
 SG_ TM2B_Reserved : 4|4@1+ (1,0) [0|15] "" Vector__XXX
 SG_ TM2B_RQPower_A : 40|16@1+ (0.1,0) [0|6553.5] "Kw" Vector__XXX
 SG_ TM2B_OutletTemp_A : 8|8@1- (1,-40) [0|0] "℃" Vector__XXX
 SG_ TM2B_InletTemp_A : 16|8@1- (1,-40) [0|0] "℃" Vector__XXX
 SG_ TM2B_FaultLevel_A : 62|2@1+ (1,0) [0|3] "" Vector__XXX
 SG_ TM2B_FaultCode_A : 56|6@1+ (1,0) [0|0] "" Vector__XXX
 SG_ T2B_WorkStatus_A : 0|2@1+ (1,0) [0|0] "" Vector__XXX
 SG_ T2B_TMS_HVRelayST_A : 2|2@1+ (1,0) [0|3] "" Vector__XXX

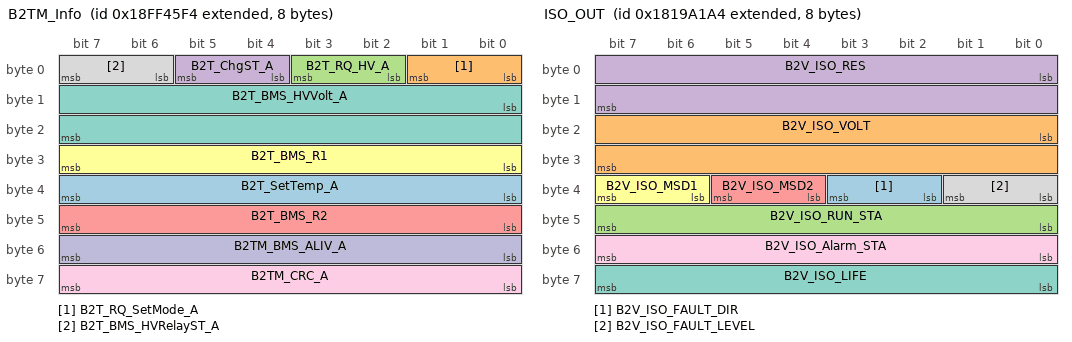
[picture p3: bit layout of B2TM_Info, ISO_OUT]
BO_ 2566866420 B2TM_Info: 8 Vector__XXX
 SG_ B2T_SetTemp_A : 32|8@1- (1,-40) [-40|215] "℃" Vector__XXX
 SG_ B2T_RQ_SetMode_A : 0|2@1+ (1,0) [0|3] "" Vector__XXX
 SG_ B2T_RQ_HV_A : 2|2@1+ (1,0) [0|3] "" Vector__XXX
 SG_ B2T_ChgST_A : 4|2@1+ (1,0) [0|3] "" Vector__XXX
 SG_ B2T_BMS_R2 : 40|8@1+ (1,0) [0|0] "" Vector__XXX
 SG_ B2T_BMS_R1 : 24|8@1+ (1,0) [0|0] "" Vector__XXX
 SG_ B2T_BMS_HVVolt_A : 8|16@1+ (1,0) [0|65535] "" Vector__XXX
 SG_ B2T_BMS_HVRelayST_A : 6|2@1+ (1,0) [0|3] "" Vector__XXX
 SG_ B2TM_CRC_A : 56|8@1+ (1,0) [0|0] "" Vector__XXX
 SG_ B2TM_BMS_ALIV_A : 48|8@1+ (1,0) [0|0] "" Vector__XXX

BO_ 2551816612 ISO_OUT: 8 Vector__XXX
 SG_ B2V_ISO_FAULT_DIR : 34|2@1- (1,0) [0|3] "" Vector__XXX
 SG_ B2V_ISO_VOLT : 16|16@1- (0.1,0) [0|6553.5] "V" Vector__XXX
 SG_ B2V_ISO_RUN_STA : 40|8@1- (1,0) [0|0] "" Vector__XXX
 SG_ B2V_ISO_RES : 0|16@1- (1,0) [0|65535] "KΩ" Vector__XXX
 SG_ B2V_ISO_MSD2 : 36|2@1- (1,0) [0|3] "" Vector__XXX
 SG_ B2V_ISO_MSD1 : 38|2@1- (1,0) [0|3] "" Vector__XXX
 SG_ B2V_ISO_LIFE : 56|8@1- (1,0) [0|0] "" Vector__XXX
 SG_ B2V_ISO_FAULT_LEVEL : 32|2@1- (1,0) [0|2] "" Vector__XXX
 SG_ B2V_ISO_Alarm_STA : 48|8@1- (1,0) [0|0] "" Vector__XXX

BO_ 2550461423 V2B_CC2: 1 Vector__XXX
 SG_ V2B_CC2_1 : 0|2@1+ (1,0) [0|0] "" Vector__XXX

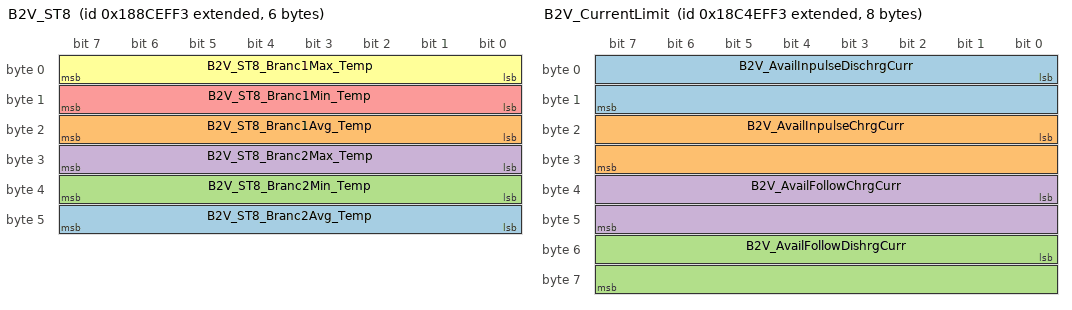
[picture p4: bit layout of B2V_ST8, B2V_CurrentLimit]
BO_ 2559373299 B2V_ST8: 6 Vector__XXX
 SG_ B2V_ST8_Branc2Avg_Temp : 40|8@1- (1,-40) [-40|215] "℃" Vector__XXX
 SG_ B2V_ST8_Branc1Avg_Temp : 16|8@1- (1,-40) [-40|215] "℃" Vector__XXX
 SG_ B2V_ST8_Branc2Min_Temp : 32|8@1- (1,-40) [-40|215] "℃" Vector__XXX
 SG_ B2V_ST8_Branc2Max_Temp : 24|8@1- (1,-40) [-40|215] "℃" Vector__XXX
 SG_ B2V_ST8_Branc1Min_Temp : 8|8@1- (1,-40) [-40|215] "℃" Vector__XXX
 SG_ B2V_ST8_Branc1Max_Temp : 0|8@1- (1,-40) [-40|215] "℃" Vector__XXX

BO_ 2563043315 B2V_CurrentLimit: 8 Vector__XXX
 SG_ B2V_AvailInpulseDischrgCurr : 0|16@1+ (0.1,0) [0|6553.5] "A" Vector__XXX
 SG_ B2V_AvailInpulseChrgCurr : 16|16@1+ (0.1,0) [0|6553.5] "A" Vector__XXX
 SG_ B2V_AvailFollowDishrgCurr : 48|16@1+ (0.1,0) [0|6553.5] "A" Vector__XXX
 SG_ B2V_AvailFollowChrgCurr : 32|16@1+ (0.1,0) [0|6553.5] "A" Vector__XXX

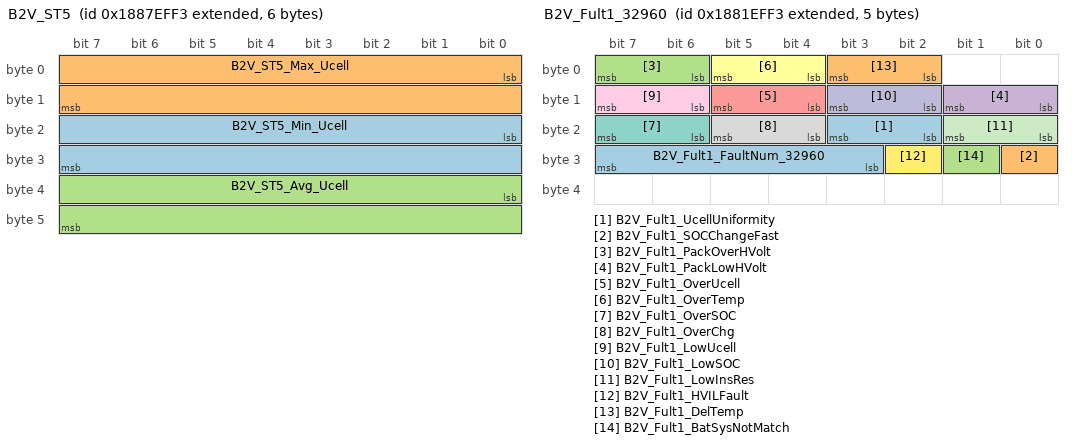
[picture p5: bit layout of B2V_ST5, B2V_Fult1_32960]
BO_ 2559045619 B2V_ST5: 6 Vector__XXX
 SG_ B2V_ST5_Min_Ucell : 16|16@1+ (0.001,0) [0|65.54] "V" Vector__XXX
 SG_ B2V_ST5_Max_Ucell : 0|16@1+ (0.001,0) [0|65.54] "V" Vector__XXX
 SG_ B2V_ST5_Avg_Ucell : 32|16@1+ (0.001,0) [0|65.54] "V" Vector__XXX

BO_ 2558783475 B2V_ST1: 8 Vector__XXX
 SG_ B2V_ST1_RechrgCycels : 46|18@1+ (1,0) [0|300000] "" Vector__XXX
 SG_ B2V_ST1_PrechrgRelaySt : 4|2@1+ (1,0) [0|3] "" Vector__XXX
 SG_ B2V_ST1_PantoChrgPosRelaySt : 18|2@1+ (1,0) [0|3] "" Vector__XXX
 SG_ B2V_ST1_PantoChrgNegRelaySt : 20|2@1+ (1,0) [0|3] "" Vector__XXX
 SG_ B2V_ST1_PantoChrgConnectSt : 37|1@1+ (1,0) [0|1] "" Vector__XXX
 SG_ B2V_ST1_MainPosRelaySt : 0|2@1+ (1,0) [0|3] "" Vector__XXX
 SG_ B2V_ST1_MainNegRelaySt : 2|2@1+ (1,0) [0|3] "" Vector__XXX
 SG_ B2V_ST1_HeatPosRelaySt : 14|2@1+ (1,0) [0|3] "" Vector__XXX
 SG_ B2V_ST1_HeatNegRelaySt : 16|2@1+ (1,0) [0|3] "" Vector__XXX
 SG_ B2V_ST1_HeatingStatus : 43|1@1+ (1,0) [0|1] "" Vector__XXX
 SG_ B2V_ST1_DCChrgPos2RelaySt : 10|2@1+ (1,0) [0|3] "" Vector__XXX
 SG_ B2V_ST1_DCChrgPos1RelaySt : 6|2@1+ (1,0) [0|3] "" Vector__XXX
 SG_ B2V_ST1_DCChrgNeg2RelaySt : 12|2@1+ (1,0) [0|3] "" Vector__XXX
 SG_ B2V_ST1_DCChrgNeg1RelaySt : 8|2@1+ (1,0) [0|3] "" Vector__XXX
 SG_ B2V_ST1_DCChrgConnectSt : 35|2@1+ (1,0) [0|3] "" Vector__XXX
 SG_ B2V_ST1_CoolingStatus : 44|2@1+ (1,0) [0|3] "" Vector__XXX
 SG_ B2V_ST1_ChrgStatus : 41|2@1+ (1,0) [0|3] "" Vector__XXX
 SG_ B2V_ST1_ChrgMode : 39|2@1+ (1,0) [0|3] "" Vector__XXX
 SG_ B2V_ST1_BMS_HVStatus : 32|2@1+ (1,0) [0|3] "" Vector__XXX
 SG_ B2V_ST1_BMS_BalanceStatus : 34|1@1+ (1,0) [0|1] "" Vector__XXX
 SG_ B2V_ST1_Aux3RelaySt : 30|2@1+ (1,0) [0|3] "" Vector__XXX
 SG_ B2V_ST1_Aux2RelaySt : 28|2@1+ (1,0) [0|3] "" Vector__XXX
 SG_ B2V_ST1_Aux1RelaySt : 26|2@1+ (1,0) [0|3] "" Vector__XXX
 SG_ B2V_ST1_ACChrgPosRelaySt : 22|2@1+ (1,0) [0|3] "" Vector__XXX
 SG_ B2V_ST1_ACChrgNegRelaySt : 24|2@1+ (1,0) [0|3] "" Vector__XXX
 SG_ B2V_ST1_ACChrgConnectSt : 38|1@1+ (1,0) [0|1] "" Vector__XXX

BO_ 2558652403 B2V_Fult1_32960: 5 Vector__XXX
 SG_ B2V_Fult1_UcellUniformity : 18|2@1+ (1,0) [0|0] "" Vector__XXX
 SG_ B2V_Fult1_SOCChangeFast : 24|1@1+ (1,0) [0|0] "" Vector__XXX
 SG_ B2V_Fult1_PackOverHVolt : 6|2@1+ (1,0) [0|0] "" Vector__XXX
 SG_ B2V_Fult1_PackLowHVolt : 8|2@1+ (1,0) [0|0] "" Vector__XXX
 SG_ B2V_Fult1_OverUcell : 12|2@1+ (1,0) [0|0] "" Vector__XXX
 SG_ B2V_Fult1_OverTemp : 4|2@1+ (1,0) [0|0] "" Vector__XXX
 SG_ B2V_Fult1_OverSOC : 22|2@1+ (1,0) [0|3] "" Vector__XXX
 SG_ B2V_Fult1_OverChg : 20|2@1+ (1,0) [0|0] "" Vector__XXX
 SG_ B2V_Fult1_LowUcell : 14|2@1+ (1,0) [0|0] "" Vector__XXX
 SG_ B2V_Fult1_LowSOC : 10|2@1+ (1,0) [0|0] "" Vector__XXX
 SG_ B2V_Fult1_LowInsRes : 16|2@1+ (1,0) [0|0] "" Vector__XXX
 SG_ B2V_Fult1_HVILFault : 26|1@1+ (1,0) [0|0] "" Vector__XXX
 SG_ B2V_Fult1_FaultNum_32960 : 27|5@1+ (1,0) [0|0] "" Vector__XXX
 SG_ B2V_Fult1_DelTemp : 2|2@1+ (1,0) [0|0] "" Vector__XXX
 SG_ B2V_Fult1_BatSysNotMatch : 25|1@1+ (1,0) [0|0] "" Vector__XXX

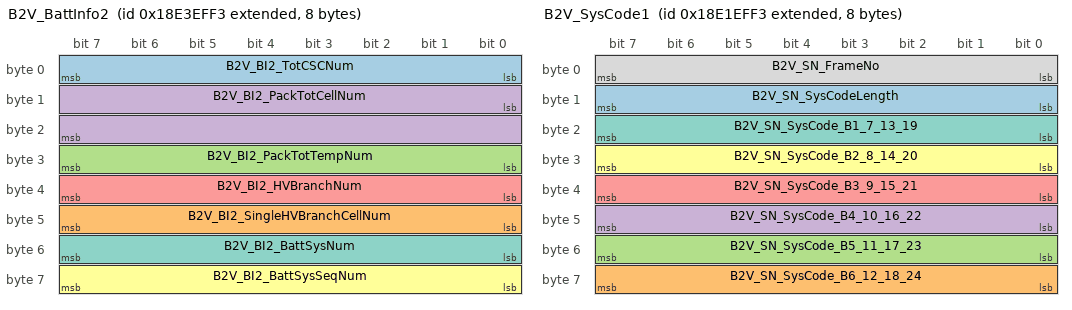
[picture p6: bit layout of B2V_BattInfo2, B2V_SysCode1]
BO_ 2565074931 B2V_BattInfo2: 8 Vector__XXX
 SG_ B2V_BI2_TotCSCNum : 0|8@1+ (1,0) [0|255] "" Vector__XXX
 SG_ B2V_BI2_SingleHVBranchCellNum : 40|8@1+ (1,0) [0|5] "" Vector__XXX
 SG_ B2V_BI2_PackTotTempNum : 24|8@1+ (1,0) [0|255] "" Vector__XXX
 SG_ B2V_BI2_PackTotCellNum : 8|16@1+ (1,0) [0|65535] "" Vector__XXX
 SG_ B2V_BI2_HVBranchNum : 32|8@1+ (1,0) [0|5] "" Vector__XXX
 SG_ B2V_BI2_BattSysSeqNum : 56|8@1+ (1,0) [0|5] "" Vector__XXX
 SG_ B2V_BI2_BattSysNum : 48|8@1+ (1,0) [0|5] "" Vector__XXX

BO_ 2564943859 B2V_SysCode1: 8 Vector__XXX
 SG_ B2V_SN_SysCodeLength : 8|8@1+ (1,0) [0|0] "" Vector__XXX
 SG_ B2V_SN_SysCode_B6_12_18_24 : 56|8@1+ (1,0) [0|0] "" Vector__XXX
 SG_ B2V_SN_SysCode_B5_11_17_23 : 48|8@1+ (1,0) [0|0] "" Vector__XXX
 SG_ B2V_SN_SysCode_B4_10_16_22 : 40|8@1+ (1,0) [0|0] "" Vector__XXX
 SG_ B2V_SN_SysCode_B3_9_15_21 : 32|8@1+ (1,0) [0|0] "" Vector__XXX
 SG_ B2V_SN_SysCode_B2_8_14_20 : 24|8@1+ (1,0) [0|0] "" Vector__XXX
 SG_ B2V_SN_SysCode_B1_7_13_19 : 16|8@1+ (1,0) [0|0] "" Vector__XXX
 SG_ B2V_SN_FrameNo : 0|8@1+ (1,0) [0|0] "" Vector__XXX

BO_ 2550263795 B2V_RQ: 1 Vector__XXX
 SG_ B2V_RQ_VIN : 0|8@1+ (1,0) [0|0] "" Vector__XXX

BO_ 2550330351 V2B_CMD: 8 Vector__XXX
 SG_ V2B_CMD_VehicleSpeed : 23|8@0+ (1,0) [0|0] "km/h" Vector__XXX
 SG_ V2B_CMD_Reserved2 : 63|2@0+ (1,0) [0|0] "" Vector__XXX
 SG_ V2B_CMD_Reserved1 : 61|2@0+ (1,0) [0|0] "" Vector__XXX
 SG_ V2B_CMD_MainPosRelayST : 25|2@0+ (1,0) [0|0] "" Vector__XXX
 SG_ V2B_CMD_MainPosRelayFlt : 27|2@0+ (1,0) [0|0] "" Vector__XXX
 SG_ V2B_CMD_MainNegRelayST : 29|2@0+ (1,0) [0|0] "" Vector__XXX
 SG_ V2B_CMD_MainNegRelayFlt : 31|2@0+ (1,0) [0|0] "" Vector__XXX
 SG_ V2B_CMD_HeatPosRelayST : 37|2@0+ (1,0) [0|0] "" Vector__XXX
 SG_ V2B_CMD_HeatPosRelayFlt : 39|2@0+ (1,0) [0|0] "" Vector__XXX
 SG_ V2B_CMD_HeatNegRelayST : 41|2@0+ (1,0) [0|0] "" Vector__XXX
 SG_ V2B_CMD_HeatNegRelayFlt : 43|2@0+ (1,0) [0|0] "" Vector__XXX
 SG_ V2B_CMD_ChrgPosRelayST : 33|2@0+ (1,0) [0|0] "" Vector__XXX
 SG_ V2B_CMD_ChrgPosRelayFlt : 35|2@0+ (1,0) [0|0] "" Vector__XXX
 SG_ V2B_CMD_Aux4RelayST : 57|2@0+ (1,0) [0|0] "" Vector__XXX
 SG_ V2B_CMD_Aux4RelayFlt : 59|2@0+ (1,0) [0|0] "" Vector__XXX
 SG_ V2B_CMD_Aux3RelayST : 53|2@0+ (1,0) [0|0] "" Vector__XXX
 SG_ V2B_CMD_Aux3RelayFlt : 55|2@0+ (1,0) [0|0] "" Vector__XXX
 SG_ V2B_CMD_Aux3OnOff : 15|2@0+ (1,0) [0|0] "" Vector__XXX
 SG_ V2B_CMD_Aux2RelayST : 49|2@0+ (1,0) [0|0] "" Vector__XXX
 SG_ V2B_CMD_Aux2RelayFlt : 51|2@0+ (1,0) [0|0] "" Vector__XXX
 SG_ V2B_CMD_Aux1RelayST : 45|2@0+ (1,0) [0|0] "" Vector__XXX
 SG_ V2B_CMD_Aux1RelayFlt : 47|2@0+ (1,0) [0|0] "" Vector__XXX
 SG_ V2B_CMD_Aux2OnOff : 13|2@0+ (1,0) [0|0] "" Vector__XXX
 SG_ V2B_CMD_Aux1OnOff : 11|2@0+ (1,0) [0|0] "" Vector__XXX
 SG_ V2B_CMD_HV_OnOff : 9|2@0+ (1,0) [0|3] "" Vector__XXX
 SG_ V2B_CMD_LifeSignal : 7|8@0+ (1,0) [0|255] "" Vector__XXX

BO_ 2550526959 V2B_Relay: 7 Vector__XXX
 SG_ V3B_KeyonRun : 55|1@1- (1,0) [0|0] "" Vector__XXX
 SG_ V3B_Keyon : 54|1@1- (1,0) [0|0] "" Vector__XXX
 SG_ V2B_AUXPreRelayFlt : 53|1@1- (1,0) [0|0] "" Vector__XXX
 SG_ V2B_AUXRelayFlt : 52|1@1- (1,0) [0|0] "" Vector__XXX
 SG_ V2B_MainAuxPreRelayFlt : 51|1@1- (1,0) [0|0] "" Vector__XXX
 SG_ V2B_MainAUXRelayFlt : 50|1@1- (1,0) [0|0] "" Vector__XXX
 SG_ V2B_AUXPreRelayST : 49|1@1- (1,0) [0|0] "" Vector__XXX
 SG_ V2B_AUXRelayST : 48|1@1- (1,0) [0|0] "" Vector__XXX
 SG_ V2B_MainAuxPreRelayST : 47|1@1- (1,0) [0|0] "" Vector__XXX
 SG_ V2B_MainAuxRelayST : 46|1@1- (1,0) [0|0] "" Vector__XXX
 SG_ V2B_MainPos6RelayFlt : 45|1@1- (1,0) [0|0] "" Vector__XXX
 SG_ V2B_MainPos5RelayFlt : 44|1@1- (1,0) [0|0] "" Vector__XXX
 SG_ V2B_MainPos4RelayFlt : 43|1@1- (1,0) [0|0] "" Vector__XXX
 SG_ V2B_MainPos3RelayFlt : 42|1@1- (1,0) [0|0] "" Vector__XXX
 SG_ V2B_MainPos2RelayFlt : 41|1@1- (1,0) [0|0] "" Vector__XXX
 SG_ V2B_MainPos1RelayFlt : 40|1@1- (1,0) [0|0] "" Vector__XXX
 SG_ V2B_MainPosRelayFlt1 : 39|1@1- (1,0) [0|0] "" Vector__XXX
 SG_ V2B_HeatNegRelayFlt1 : 38|1@1- (1,0) [0|0] "" Vector__XXX
 SG_ V2B_HeatPosRelayFlt1 : 37|1@1- (1,0) [0|0] "" Vector__XXX
 SG_ V2B_ChgNeg4RelayFlt : 36|1@1- (1,0) [0|0] "" Vector__XXX
 SG_ V2B_ChgPos4RelayFlt : 35|1@1- (1,0) [0|0] "" Vector__XXX
 SG_ V2B_ChgNeg3RelayFlt : 34|1@1- (1,0) [0|0] "" Vector__XXX
 SG_ V2B_ChgPos3RelayFlt : 33|1@1- (1,0) [0|0] "" Vector__XXX
 SG_ V2B_ChgNeg2RelayFlt : 32|1@1- (1,0) [0|0] "" Vector__XXX
 SG_ V2B_ChgPos2RelayFlt : 31|1@1- (1,0) [0|0] "" Vector__XXX
 SG_ V2B_ChgNeg1RelayFlt : 30|1@1- (1,0) [0|0] "" Vector__XXX
 SG_ V2B_ChgPos1RelayFlt : 29|1@1- (1,0) [0|0] "" Vector__XXX
 SG_ V2B_MainNegRelayFlt1 : 28|1@1- (1,0) [0|0] "" Vector__XXX
 SG_ V7B_MainPos : 27|1@1- (1,0) [0|0] "" Vector__XXX
 SG_ V6B_MainPos : 26|1@1- (1,0) [0|0] "" Vector__XXX
 SG_ V5B_MainPos : 25|1@1- (1,0) [0|0] "" Vector__XXX
 SG_ V4B_MainPos : 24|1@1- (1,0) [0|0] "" Vector__XXX
 SG_ V3B_MainPos : 23|1@1- (1,0) [0|0] "" Vector__XXX
 SG_ V2B_MainPos : 22|1@1- (1,0) [-1|0] "" Vector__XXX
 SG_ V2B_HeatNegRelaySt : 20|2@1- (1,0) [0|0] "" Vector__XXX
 SG_ V2B_HeatPosRelaySt : 18|2@1- (1,0) [0|0] "" Vector__XXX
 SG_ V2B_DCChrgNeg4RelaySt : 16|2@1- (1,0) [0|0] "" Vector__XXX
 SG_ V2B_DCChrgPos4RelaySt : 14|2@1- (1,0) [0|0] "" Vector__XXX
 SG_ V2B_DCChrgNeg3RelaySt : 12|2@1- (1,0) [0|0] "" Vector__XXX
 SG_ V2B_DCChrgPos3RelaySt : 10|2@1- (1,0) [0|0] "" Vector__XXX
 SG_ V2B_DCChrgNeg2RelaySt : 8|2@1- (1,0) [0|0] "" Vector__XXX
 SG_ V2B_DCChrgPos2RelaySt : 6|2@1+ (1,0) [0|0] "" Vector__XXX
 SG_ V2B_DCChrgNeg1RelaySt : 4|2@1- (1,0) [0|0] "" Vector__XXX
 SG_ V2B_DCChrgPos1RelaySt : 2|2@1+ (1,0) [0|0] "" Vector__XXX
 SG_ V2B_MainNegRelaySt : 0|2@1+ (1,0) [0|0] "" Vector__XXX

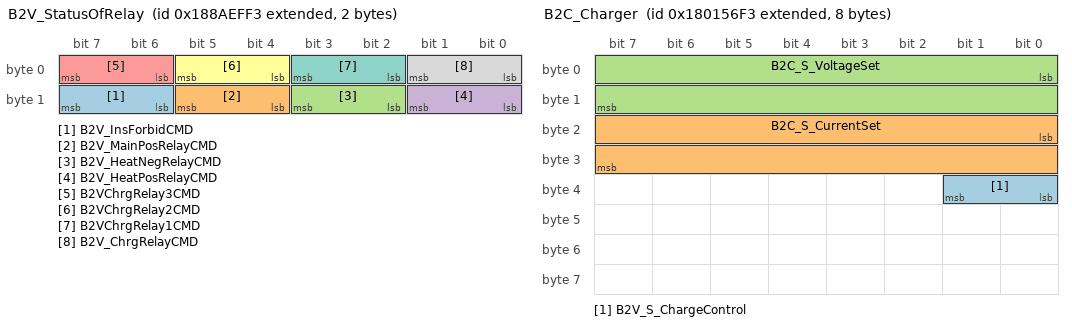
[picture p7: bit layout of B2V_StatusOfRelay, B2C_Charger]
BO_ 2559242227 B2V_StatusOfRelay: 2 Vector__XXX
 SG_ B2V_InsForbidCMD : 14|2@1+ (1,0) [0|3] "" Vector__XXX
 SG_ B2V_MainPosRelayCMD : 12|2@1+ (1,0) [0|3] "" Vector__XXX
 SG_ B2V_HeatNegRelayCMD : 10|2@1+ (1,0) [0|3] "" Vector__XXX
 SG_ B2V_HeatPosRelayCMD : 8|2@1+ (1,0) [0|3] "" Vector__XXX
 SG_ B2VChrgRelay3CMD : 6|2@1+ (1,0) [0|3] "" Vector__XXX
 SG_ B2VChrgRelay2CMD : 4|2@1+ (1,0) [0|3] "" Vector__XXX
 SG_ B2VChrgRelay1CMD : 2|2@1+ (1,0) [0|3] "" Vector__XXX
 SG_ B2V_ChrgRelayCMD : 0|2@1+ (1,0) [0|3] "" Vector__XXX

BO_ 2550224627 B2C_Charger: 8 Vector__XXX
 SG_ B2V_S_ChargeControl : 32|2@1+ (1,0) [0|0] "" Vector__XXX
 SG_ B2C_S_CurrentSet : 16|16@1+ (0.1,0) [0|6553.5] "A" Vector__XXX
 SG_ B2C_S_VoltageSet : 0|16@1+ (0.1,0) [0|6553.5] "V" Vector__XXX

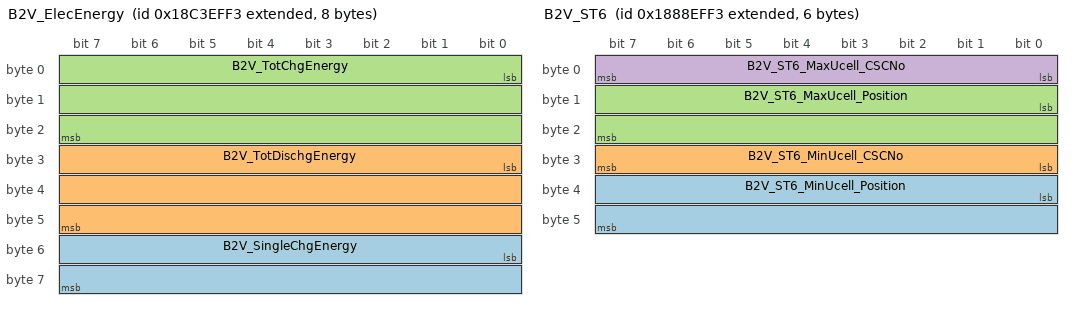
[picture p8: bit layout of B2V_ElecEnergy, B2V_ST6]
BO_ 2562977779 B2V_ElecEnergy: 8 Vector__XXX
 SG_ B2V_SingleChgEnergy : 48|16@1+ (1,0) [0|65535] "KWh" Vector__XXX
 SG_ B2V_TotDischgEnergy : 24|24@1+ (1,0) [0|16777215] "KWh" Vector__XXX
 SG_ B2V_TotChgEnergy : 0|24@1+ (1,0) [0|16777215] "KWh" Vector__XXX

BO_ 2559111155 B2V_ST6: 6 Vector__XXX
 SG_ B2V_ST6_MinUcell_Position : 32|16@1+ (1,0) [0|0] "" Vector__XXX
 SG_ B2V_ST6_MinUcell_CSCNo : 24|8@1+ (1,0) [0|0] "" Vector__XXX
 SG_ B2V_ST6_MaxUcell_Position : 8|16@1+ (1,0) [0|0] "" Vector__XXX
 SG_ B2V_ST6_MaxUcell_CSCNo : 0|8@1+ (1,0) [0|0] "" Vector__XXX

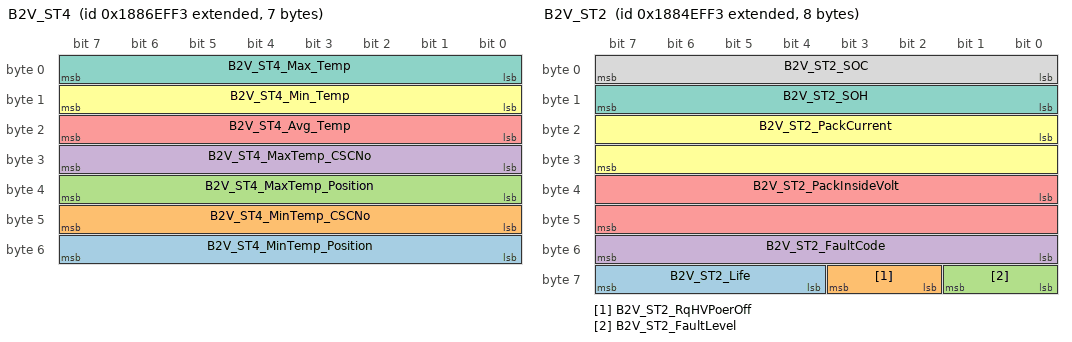
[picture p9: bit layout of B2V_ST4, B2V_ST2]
BO_ 2558980083 B2V_ST4: 7 Vector__XXX
 SG_ B2V_ST4_MinTemp_Position : 48|8@1+ (1,0) [0|0] "" Vector__XXX
 SG_ B2V_ST4_MinTemp_CSCNo : 40|8@1+ (1,0) [0|255] "" Vector__XXX
 SG_ B2V_ST4_MaxTemp_Position : 32|8@1+ (1,0) [0|0] "" Vector__XXX
 SG_ B2V_ST4_MaxTemp_CSCNo : 24|8@1+ (1,0) [0|255] "" Vector__XXX
 SG_ B2V_ST4_Avg_Temp : 16|8@1- (1,-40) [-40|215] "℃" Vector__XXX
 SG_ B2V_ST4_Min_Temp : 8|8@1- (1,-40) [-40|215] "℃" Vector__XXX
 SG_ B2V_ST4_Max_Temp : 0|8@1- (1,-40) [-40|215] "℃" Vector__XXX

BO_ 2558849011 B2V_ST2: 8 Vector__XXX
 SG_ B2V_ST2_Life : 60|4@1+ (1,0) [0|0] "" Vector__XXX
 SG_ B2V_ST2_RqHVPoerOff : 58|2@1+ (1,0) [0|0] "" Vector__XXX
 SG_ B2V_ST2_FaultLevel : 56|2@1+ (1,0) [0|0] "" Vector__XXX
 SG_ B2V_ST2_FaultCode : 48|8@1+ (1,0) [0|0] "" Vector__XXX
 SG_ B2V_ST2_PackInsideVolt : 32|16@1+ (0.1,0) [0|6553.5] "V" Vector__XXX
 SG_ B2V_ST2_PackCurrent : 16|16@1- (0.1,-1600) [-1600|1600] "A" Vector__XXX
 SG_ B2V_ST2_SOH : 8|8@1+ (0.4,0) [0|100] "%" Vector__XXX
 SG_ B2V_ST2_SOC : 0|8@1+ (0.4,0) [0|100] "%" Vector__XXX

BO_ 2558717939 B2V_Fult2: 8 Vector__XXX
 SG_ B2V_Fult2_Reserved2 : 63|1@1- (1,0) [0|0] "" Vector__XXX
 SG_ B2V_Fult2_Reserved1 : 62|1@1- (1,0) [0|0] "" Vector__XXX
 SG_ B2V_Fult2_ContiCurrOverLoad : 60|2@1- (1,0) [0|0] "" Vector__XXX
 SG_ B2V_Fult2_SOCDifferErr : 59|1@1- (1,0) [0|0] "" Vector__XXX
 SG_ B2V_Fult2_ContiChrgCurrOverLoad : 57|2@1- (1,0) [0|0] "" Vector__XXX
 SG_ B2V_Fult2_FireDetectorErr : 56|1@1- (1,0) [0|0] "" Vector__XXX
 SG_ B2V_Fult2_ELockErr : 55|1@1- (1,0) [0|0] "" Vector__XXX
 SG_ B2V_Fult2_ChrgNTCTempOver : 53|2@1- (1,0) [0|0] "" Vector__XXX
 SG_ B2V_Fult2_ChrgNTCErr : 52|1@1- (1,0) [0|0] "" Vector__XXX
 SG_ B2V_Fult2_OverChrgCurrInTheChrg : 51|1@1- (1,0) [0|0] "" Vector__XXX
 SG_ B2V_Fult2_OverCurrWhenInCh : 50|1@1- (1,0) [0|0] "" Vector__XXX
 SG_ B2V_Fult2_ChrgConnectErr : 49|1@1- (1,0) [0|0] "" Vector__XXX
 SG_ B2V_Fult2_PanChrgNegRelOpEr : 47|1@1- (1,0) [0|0] "" Vector__XXX
 SG_ B2V_Fult2_PantoChrgNegRelWeldErr : 48|1@1- (1,0) [0|0] "" Vector__XXX
 SG_ B2V_Fult2_PantoChrgPosRelWeldErr : 46|1@1- (1,0) [0|0] "" Vector__XXX
 SG_ B2V_Fult2_DCChrgPos4RelayOpenErr : 45|1@1- (1,0) [0|0] "" Vector__XXX
 SG_ B2V_Fult2_DCChrgNeg3RelayWeldErr : 44|1@1- (1,0) [0|0] "" Vector__XXX
 SG_ B2V_Fult2_DCChrgNeg3RelayOpenErr : 43|1@1- (1,0) [0|0] "" Vector__XXX
 SG_ B2V_Fult2_DCChrgPos3RelayWeldErr : 42|1@1- (1,0) [0|0] "" Vector__XXX
 SG_ B2V_Fult2_DCChrgPos3RelayOpenErr : 41|1@1- (1,0) [0|0] "" Vector__XXX
 SG_ B2V_Fult2_DCChrgNeg2RelayWeldErr : 40|1@1- (1,0) [0|0] "" Vector__XXX
 SG_ B2V_Fult2_DCChrgNeg2RelayOpenErr : 39|1@1- (1,0) [0|0] "" Vector__XXX
 SG_ B2V_Fult2_DCChrgPos2RelayWeldErr : 38|1@1- (1,0) [0|0] "" Vector__XXX
 SG_ B2V_Fult2_DCChrgPos2RelayOpenErr : 37|1@1- (1,0) [0|0] "" Vector__XXX
 SG_ B2V_Fult2_DCChrgNeg1RelayWeldErr : 36|1@1- (1,0) [0|0] "" Vector__XXX
 SG_ B2V_Fult2_DCChrgNeg1RelayOpenErr : 35|1@1- (1,0) [0|0] "" Vector__XXX
 SG_ B2V_Fult2_DCChrgPos1RelayWeldErr : 34|1@1- (1,0) [0|0] "" Vector__XXX
 SG_ B2V_Fult2_DCChrgPos1RelayOpenErr : 33|1@1- (1,0) [0|0] "" Vector__XXX
 SG_ B2V_Fult2_MainNegRelayWeldErr : 32|1@1- (1,0) [0|0] "" Vector__XXX
 SG_ B2V_Fult2_MainNegRelayOpenErr : 31|1@1- (1,0) [0|0] "" Vector__XXX
 SG_ B2V_Fult2_MainPosRelayWeldErr : 30|1@1- (1,0) [0|0] "" Vector__XXX
 SG_ B2V_Fult2_MainPosRelayOpenErr : 29|1@1- (1,0) [0|0] "" Vector__XXX
 SG_ B2V_Fult2_HeatRelayWeldErr : 28|1@1- (1,0) [0|0] "" Vector__XXX
 SG_ B2V_Fult2_HeatRelayOpenErr : 27|1@1- (1,0) [0|0] "" Vector__XXX
 SG_ B2V_Fult2_BranchBreakErr : 26|1@1- (1,0) [0|0] "" Vector__XXX
 SG_ B2V_Fult2_DCDCErr : 25|1@1- (1,0) [0|0] "" Vector__XXX
 SG_ B2V_Fult2_InnerCommunicationErr : 24|1@1- (1,0) [0|0] "" Vector__XXX
 SG_ B2V_Fult2_ACANLost : 23|1@1- (1,0) [0|0] "" Vector__XXX
 SG_ B2V_Fult2_ChrgInsLowErr : 22|1@1- (1,0) [0|0] "" Vector__XXX
 SG_ B2V_Fult2_AuxLoopPrechrgErr : 21|1@1- (1,0) [0|0] "" Vector__XXX
 SG_ B2V_Fult2_MainLoopPrechrgErr : 20|1@1- (1,0) [0|0] "" Vector__XXX
 SG_ B2V_Fult2_PackSelfProtect : 19|1@1- (1,0) [0|0] "" Vector__XXX
 SG_ B2V_Fult2_HeatungFilmErr : 18|1@1- (1,0) [0|0] "" Vector__XXX
 SG_ B2V_Fult2_TMSErr : 17|1@1- (1,0) [0|0] "" Vector__XXX
 SG_ B2V_Fult2_PowerSupplyErr : 16|1@1- (1,0) [0|0] "" Vector__XXX
 SG_ B2V_Fult2_CurrSensorErr : 15|1@1- (1,0) [0|0] "" Vector__XXX
 SG_ B2V_Fult2_OverChrgCurrInTheDrive : 13|2@1- (1,0) [0|0] "" Vector__XXX
 SG_ B2V_Fult2_OverDischrgCurr : 11|2@1- (1,0) [0|0] "" Vector__XXX
 SG_ B2V_Fult2_PackFireWarning : 10|1@1- (1,0) [0|0] "" Vector__XXX
 SG_ B2V_Fult2_CellLowTemp : 9|1@1- (1,0) [0|0] "" Vector__XXX
 SG_ B2V_Fult2_CellOverDischrg : 8|1@1- (1,0) [0|0] "" Vector__XXX
 SG_ B2V_Fult2_FaultNum : 0|8@1- (1,0) [0|0] "" Vector__XXX

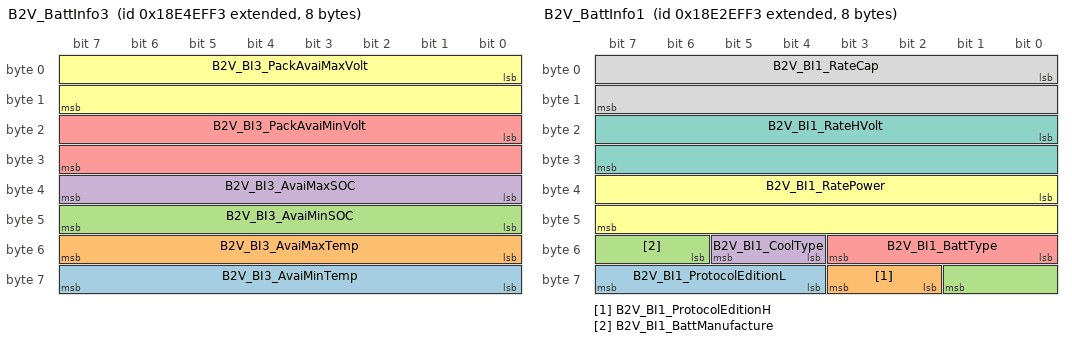
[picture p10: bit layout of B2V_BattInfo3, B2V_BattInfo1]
BO_ 2565140467 B2V_BattInfo3: 8 Vector__XXX
 SG_ B2V_BI3_AvaiMinTemp : 56|8@1+ (1,-40) [-40|215] "℃" Vector__XXX
 SG_ B2V_BI3_AvaiMaxTemp : 48|8@1+ (1,-40) [-40|215] "℃" Vector__XXX
 SG_ B2V_BI3_AvaiMinSOC : 40|8@1+ (0.4,0) [0|102] "%" Vector__XXX
 SG_ B2V_BI3_AvaiMaxSOC : 32|8@1+ (0.4,0) [0|102] "%" Vector__XXX
 SG_ B2V_BI3_PackAvaiMinVolt : 16|16@1+ (0.1,0) [0|6554] "V" Vector__XXX
 SG_ B2V_BI3_PackAvaiMaxVolt : 0|16@1+ (0.1,0) [0|6553.5] "V" Vector__XXX

BO_ 2565009395 B2V_BattInfo1: 8 Vector__XXX
 SG_ B2V_BI1_ProtocolEditionL : 60|4@1- (1,0) [0|0] "" Vector__XXX
 SG_ B2V_BI1_ProtocolEditionH : 58|2@1- (1,0) [0|0] "" Vector__XXX
 SG_ B2V_BI1_BattManufacture : 54|4@1- (1,0) [0|0] "" Vector__XXX
 SG_ B2V_BI1_CoolType : 52|2@1- (1,0) [0|0] "" Vector__XXX
 SG_ B2V_BI1_BattType : 48|4@1- (1,0) [0|0] "" Vector__XXX
 SG_ B2V_BI1_RatePower : 32|16@1+ (0.1,0) [0|6554] "KWh" Vector__XXX
 SG_ B2V_BI1_RateHVolt : 16|16@1+ (0.1,0) [0|6553.5] "V" Vector__XXX
 SG_ B2V_BI1_RateCap : 0|16@1+ (0.1,0) [0|6553.5] "Ah" Vector__XXX

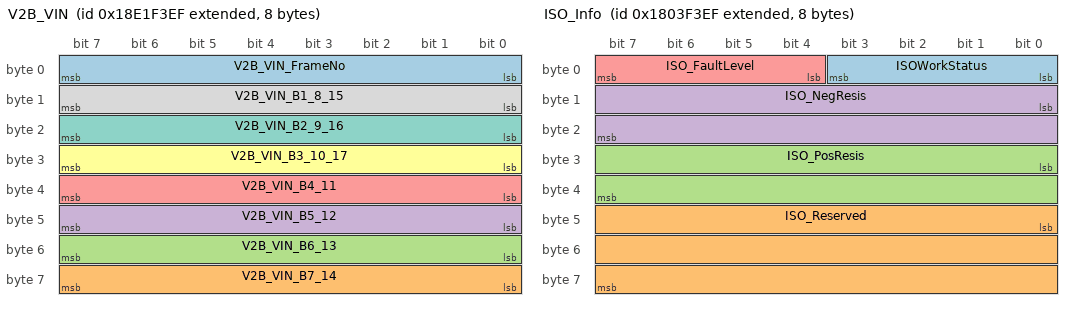
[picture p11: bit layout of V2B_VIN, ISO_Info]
BO_ 2564944879 V2B_VIN: 8 Vector__XXX
 SG_ V2B_VIN_FrameNo : 0|8@1- (1,0) [0|0] "" Vector__XXX
 SG_ V2B_VIN_B7_14 : 56|8@1- (1,0) [0|0] "" Vector__XXX
 SG_ V2B_VIN_B6_13 : 48|8@1- (1,0) [0|0] "" Vector__XXX
 SG_ V2B_VIN_B5_12 : 40|8@1- (1,0) [0|0] "" Vector__XXX
 SG_ V2B_VIN_B4_11 : 32|8@1- (1,0) [0|0] "" Vector__XXX
 SG_ V2B_VIN_B3_10_17 : 24|8@1- (1,0) [0|0] "" Vector__XXX
 SG_ V2B_VIN_B2_9_16 : 16|8@1- (1,0) [0|0] "" Vector__XXX
 SG_ V2B_VIN_B1_8_15 : 8|8@1- (1,0) [0|255] "" Vector__XXX

BO_ 2550395887 ISO_Info: 8 Vector__XXX
 SG_ ISOWorkStatus : 0|4@1- (1,0) [0|15] "" Vector__XXX
 SG_ ISO_Reserved : 40|24@1- (1,0) [0|0] "" Vector__XXX
 SG_ ISO_PosResis : 24|16@1- (1,0) [0|60000] "KΩ" Vector__XXX
 SG_ ISO_NegResis : 8|16@1- (1,0) [0|60000] "KΩ" Vector__XXX
 SG_ ISO_FaultLevel : 4|4@1- (1,0) [0|15] "" Vector__XXX

CM_ SG_ 2585788163 V2B_ISO_SET_CHEK_T "0X55";
CM_ SG_ 2585788163 V2B_ISO_SET_CHEK_S "0X54";
CM_ SG_ 2585788163 V2B_ISO_SET_CHEK_INSTRU "0绝缘关闭255持续检测 1-254为检测次数";
CM_ SG_ 2585788163 V2B_ISO_SET_CHEK_B "0X42";
CM_ SG_ 2585788163 V2B_ISO_SET_CHEK_A "0X41";
CM_ SG_ 2550330351 V2B_CMD_VehicleSpeed "车速";
VAL_ 2566800884 B2T_RQ_SetMode_A 3 "Self-Loop Mode" 2 "Heat Mode" 1 "Cooling Mode" 0 "Shutdown Mode" ;
VAL_ 2566800884 B2T_RQ_HV_A 3 "Invalid" 2 "Invalid" 1 "HV Off Request" 0 "HV On Request" ;
VAL_ 2566800884 B2T_ChgST_A 3 "Invalid" 2 "Invalid" 1 "Charging mode" 0 "Non-Charging mode" ;
VAL_ 2566800884 B2T_BMS_HVRelayST_A 3 "Invalid" 2 "Invalid" 1 "下高压" 0 "上高压" ;
VAL_ 2566832442 TM2B_FaultLevel_A 0 "Normal" 3 "Level 3 Fault" 2 "Level 2 Fault" 1 "Level 1 Fault" ;
VAL_ 2566832442 TM2B_FaultCode_A 57 "压缩机失速" 56 "压缩机 2 故障" 55 "压缩机故障" 51 "母线欠压" 50 "排气温度传感器故障" 49 "高压总回路接触器故障" 48 "BMS 和 TMS CAN 通讯异常" 47 "DCDC 供电故障" 42 "从机组 2 丢失" 40 "从机组 2 二级故障" 39 "从机组 2 一级故障" 38 "从机组 1 丢失" 36 "从机组 1 二级故障" 35 "从机组 1 一级故障" 34 "DCDC 故障" 33 "K2 继电器故障" 32 "高压预冲故障" 31 "PTC 通讯故障" 30 "水位低报警" 28 "ATS 水泵故障" 27 "水泵故障" 26 "压缩机 2 通讯故障" 25 "机组出水温度传感器" 24 "机组进水温度传感器" 23 "低压传感器" 22 "高压传感器" 21 "风扇故障" 19 "压缩机通讯故障" 3 "面板空调故障" 2 "PTC 故障" 1 "PTC 高级故障" 0 "无故障" ;
VAL_ 2566832442 T2B_WorkStatus_A 3 "Self-Loop Mode" 2 "Heat

Mode" 1 "Cooling Mode" 0 "Shutdown Mode" ;
VAL_ 2566832442 T2B_TMS_HVRelayST_A 1 "Close" 0 "Open" ;
VAL_ 2566897978 TM2B_FaultLevel_A 0 "Normal" 3 "Level 3 Fault" 2 "Level 2 Fault" 1 "Level 1 Fault" ;
VAL_ 2566897978 TM2B_FaultCode_A 57 "压缩机失速" 56 "压缩机 2 故障" 55 "压缩机故障" 51 "母线欠压" 50 "排气温度传感器故障" 49 "高压总回路接触器故障" 48 "BMS 和 TMS CAN 通讯异常" 47 "DCDC 供电故障" 42 "从机组 2 丢失" 40 "从机组 2 二级故障" 39 "从机组 2 一级故障" 38 "从机组 1 丢失" 36 "从机组 1 二级故障" 35 "从机组 1 一级故障" 34 "DCDC 故障" 33 "K2 继电器故障" 32 "高压预冲故障" 31 "PTC 通讯故障" 30 "水位低报警" 28 "ATS 水泵故障" 27 "水泵故障" 26 "压缩机 2 通讯故障" 25 "机组出水温度传感器" 24 "机组进水温度传感器" 23 "低压传感器" 22 "高压传感器" 21 "风扇故障" 19 "压缩机通讯故障" 3 "面板空调故障" 2 "PTC 故障" 1 "PTC 高级故障" 0 "无故障" ;
VAL_ 2566897978 T2B_WorkStatus_A 3 "Self-Loop Mode" 2 "Heat

Mode" 1 "Cooling Mode" 0 "Shutdown Mode" ;
VAL_ 2566897978 T2B_TMS_HVRelayST_A 1 "Close" 0 "Open" ;
VAL_ 2566866420 B2T_RQ_SetMode_A 3 "Self-Loop Mode" 2 "Heat Mode" 1 "Cooling Mode" 0 "Shutdown Mode" ;
VAL_ 2566866420 B2T_RQ_HV_A 3 "Invalid" 2 "Invalid" 1 "HV Off Request" 0 "HV On Request" ;
VAL_ 2566866420 B2T_ChgST_A 3 "Invalid" 2 "Invalid" 1 "Charging mode" 0 "Non-Charging mode" ;
VAL_ 2566866420 B2T_BMS_HVRelayST_A 3 "Invalid" 2 "Invalid" 1 "下高压" 0 "上高压" ;
VAL_ 2551816612 B2V_ISO_FAULT_DIR 2 "偏负母线故障" 1 "偏正母线故障" 0 "无故障" ;
VAL_ 2551816612 B2V_ISO_RUN_STA 170 "正常运行" 85 "绝缘功能关闭" ;
VAL_ 2551816612 B2V_ISO_MSD2 1 "有输入" 0 "无输入" ;
VAL_ 2551816612 B2V_ISO_MSD1 1 "有故障" 0 "无故障" ;
VAL_ 2551816612 B2V_ISO_Alarm_STA 170 "无绝缘故障" 85 "有绝缘故障" ;
VAL_ 2550461423 V2B_CC2_1 1 "Connected" 0 "Not connected" ;
VAL_ 2558783475 B2V_ST1_PrechrgRelaySt 3 "Signal Invalid" 2 "Closed" 1 "Opened" 0 "Reserved" ;
VAL_ 2558783475 B2V_ST1_PantoChrgPosRelaySt 3 "Signal Invalid" 2 "Closed" 1 "Opened" 0 "Reserved" ;
VAL_ 2558783475 B2V_ST1_PantoChrgNegRelaySt 3 "Signal Invalid" 2 "Closed" 1 "Opened" 0 "Reserved" ;
VAL_ 2558783475 B2V_ST1_PantoChrgConnectSt 1 "Connected" 0 "Not connected" ;
VAL_ 2558783475 B2V_ST1_MainPosRelaySt 3 "Signal Invalid" 2 "Closed" 1 "Opened" 0 "Reserved" ;
VAL_ 2558783475 B2V_ST1_MainNegRelaySt 3 "Signal Invalid" 2 "Closed" 1 "Opened" 0 "Reserved" ;
VAL_ 2558783475 B2V_ST1_HeatPosRelaySt 3 "Signal Invalid" 2 "Closed" 1 "Opened" 0 "Reserved" ;
VAL_ 2558783475 B2V_ST1_HeatNegRelaySt 3 "Signal Invalid" 2 "Closed" 1 "Opened" 0 "Reserved" ;
VAL_ 2558783475 B2V_ST1_HeatingStatus 1 "heating" 0 "not heat" ;
VAL_ 2558783475 B2V_ST1_DCChrgPos2RelaySt 3 "Signal Invalid" 2 "Closed" 1 "Opened" 0 "Reserved" ;
VAL_ 2558783475 B2V_ST1_DCChrgPos1RelaySt 3 "Signal Invalid" 2 "Closed" 1 "Opened" 0 "Reserved" ;
VAL_ 2558783475 B2V_ST1_DCChrgNeg2RelaySt 3 "Signal Invalid" 2 "Closed" 1 "Opened" 0 "Reserved" ;
VAL_ 2558783475 B2V_ST1_DCChrgNeg1RelaySt 3 "Signal Invalid" 2 "Closed" 1 "Opened" 0 "Reserved" ;
VAL_ 2558783475 B2V_ST1_DCChrgConnectSt 3 "Invalid" 2 "double gun connect" 1 "single gun connect" 0 "Not connected" ;
VAL_ 2558783475 B2V_ST1_CoolingStatus 1 "cooling" 0 "not cooling" ;
VAL_ 2558783475 B2V_ST1_ChrgStatus 3 "Charge error" 2 "Charge Finished" 1 "Charging" 0 "not charging" ;
VAL_ 2558783475 B2V_ST1_ChrgMode 3 "Other charging" 2 "AC charging" 1 "DC charging" 0 "Notcharging" ;
VAL_ 2558783475 B2V_ST1_BMS_HVStatus 3 "Fail to HV on" 2 "HV closed" 1 "Precharge or Precheck" 0 "HV open" ;
VAL_ 2558783475 B2V_ST1_BMS_BalanceStatus 1 "Balancing" 0 "No Balancing" ;
VAL_ 2558783475 B2V_ST1_Aux3RelaySt 3 "Signal Invalid" 2 "Closed" 1 "Opened" 0 "Reserved" ;
VAL_ 2558783475 B2V_ST1_Aux2RelaySt 3 "Signal Invalid" 2 "Closed" 1 "Opened" 0 "Reserved" ;
VAL_ 2558783475 B2V_ST1_Aux1RelaySt 3 "Signal Invalid" 2 "Closed" 1 "Opened" 0 "Reserved" ;
VAL_ 2558783475 B2V_ST1_ACChrgPosRelaySt 3 "Signal Invalid" 2 "Closed" 1 "Opened" 0 "Reserved" ;
VAL_ 2558783475 B2V_ST1_ACChrgNegRelaySt 3 "Signal Invalid" 2 "Closed" 1 "Opened" 0 "Reserved" ;
VAL_ 2558783475 B2V_ST1_ACChrgConnectSt 1 "Connected" 0 "Not connected" ;
VAL_ 2558652403 B2V_Fult1_UcellUniformity 3 "Level 3 - Most severe fault" 2 "Level 2- More severe fault" 1 "Level 1-Light fault" 0 "Normal" ;
VAL_ 2558652403 B2V_Fult1_SOCChangeFast 2 "Fault" 0 "Normal" ;
VAL_ 2558652403 B2V_Fult1_PackOverHVolt 3 "Level 3 - Most severe fault" 2 "Level 2- More severe fault" 1 "Level 1-Light fault" 0 "Normal" ;
VAL_ 2558652403 B2V_Fult1_PackLowHVolt 3 "Level 3 - Most severe fault" 2 "Level 2- More severe fault" 1 "Level 1-Light fault" 0 "Normal" ;
VAL_ 2558652403 B2V_Fult1_OverUcell 3 "Level 3 - Most severe fault" 2 "Level 2- More severe fault" 1 "Level 1-Light fault" 0 "Normal" ;
VAL_ 2558652403 B2V_Fult1_OverTemp 3 "Level 3 - Most severe fault" 2 "Level 2- More severe fault" 1 "Level 1-Light fault" 0 "Normal" ;
VAL_ 2558652403 B2V_Fult1_OverSOC 3 "Level 3 - Most severe fault" 2 "Level 2- More severe fault" 1 "Level 1-Light fault" 0 "Normal" ;
VAL_ 2558652403 B2V_Fult1_OverChg 3 "Level 3 - Most severe fault" 2 "Level 2- More severe fault" 1 "Level 1-Light fault" 0 "Normal" ;
VAL_ 2558652403 B2V_Fult1_LowUcell 3 "Level 3 - Most severe fault" 2 "Level 2- More severe fault" 1 "Level 1-Light fault" 0 "Normal" ;
VAL_ 2558652403 B2V_Fult1_LowSOC 3 "Level 3 - Most severe fault" 2 "Level 2- More severe fault" 1 "Level 1-Light fault" 0 "Normal" ;
VAL_ 2558652403 B2V_Fult1_LowInsRes 3 "Level 3 - Most severe fault" 2 "Level 2- More severe fault" 1 "Level 1-Light fault" 0 "Normal" ;
VAL_ 2558652403 B2V_Fult1_HVILFault 2 "Fault" 0 "Normal" ;
VAL_ 2558652403 B2V_Fult1_DelTemp 3 "Level 3 - Most severe fault" 2 "Level 2- More severe fault" 1 "Level 1-Light fault" 0 "Normal" ;
VAL_ 2558652403 B2V_Fult1_BatSysNotMatch 2 "Fault" 0 "Normal" ;
VAL_ 2564943859 B2V_SN_SysCode_B6_12_18_24 90 "Z" 89 "Y" 88 "X" 87 "W" 86 "V" 85 "U" 84 "T" 83 "S" 82 "R" 81 "Q" 80 "P" 79 "O" 78 "N" 77 "M" 76 "L" 75 "K" 74 "J" 73 "I" 72 "H" 71 "G" 70 "F" 69 "E" 68 "D" 67 "C" 66 "B" 65 "A" 57 "9" 56 "8" 55 "7" 54 "6" 53 "5" 52 "4" 51 "3" 50 "2" 49 "1" 48 "0" ;
VAL_ 2564943859 B2V_SN_SysCode_B5_11_17_23 90 "Z" 89 "Y" 88 "X" 87 "W" 86 "V" 85 "U" 84 "T" 83 "S" 82 "R" 81 "Q" 80 "P" 79 "O" 78 "N" 77 "M" 76 "L" 75 "K" 74 "J" 73 "I" 72 "H" 71 "G" 70 "F" 69 "E" 68 "D" 67 "C" 66 "B" 65 "A" 57 "9" 56 "8" 55 "7" 54 "6" 53 "5" 52 "4" 51 "3" 50 "2" 49 "1" 48 "0" ;
VAL_ 2564943859 B2V_SN_SysCode_B4_10_16_22 90 "Z" 89 "Y" 88 "X" 87 "W" 86 "V" 85 "U" 84 "T" 83 "S" 82 "R" 81 "Q" 80 "P" 79 "O" 78 "N" 77 "M" 76 "L" 75 "K" 74 "J" 73 "I" 72 "H" 71 "G" 70 "F" 69 "E" 68 "D" 67 "C" 66 "B" 65 "A" 57 "9" 56 "8" 55 "7" 54 "6" 53 "5" 52 "4" 51 "3" 50 "2" 49 "1" 48 "0" ;
VAL_ 2564943859 B2V_SN_SysCode_B3_9_15_21 90 "Z" 89 "Y" 88 "X" 87 "W" 86 "V" 85 "U" 84 "T" 83 "S" 82 "R" 81 "Q" 80 "P" 79 "O" 78 "N" 77 "M" 76 "L" 75 "K" 74 "J" 73 "I" 72 "H" 71 "G" 70 "F" 69 "E" 68 "D" 67 "C" 66 "B" 65 "A" 57 "9" 56 "8" 55 "7" 54 "6" 53 "5" 52 "4" 51 "3" 50 "2" 49 "1" 48 "0" ;
VAL_ 2564943859 B2V_SN_SysCode_B2_8_14_20 90 "Z" 89 "Y" 88 "X" 87 "W" 86 "V" 85 "U" 84 "T" 83 "S" 82 "R" 81 "Q" 80 "P" 79 "O" 78 "N" 77 "M" 76 "L" 75 "K" 74 "J" 73 "I" 72 "H" 71 "G" 70 "F" 69 "E" 68 "D" 67 "C" 66 "B" 65 "A" 57 "9" 56 "8" 55 "7" 54 "6" 53 "5" 52 "4" 51 "3" 50 "2" 49 "1" 48 "0" ;
VAL_ 2564943859 B2V_SN_SysCode_B1_7_13_19 90 "Z" 89 "Y" 88 "X" 87 "W" 86 "V" 85 "U" 84 "T" 83 "S" 82 "R" 81 "Q" 80 "P" 79 "O" 78 "N" 77 "M" 76 "L" 75 "K" 74 "J" 73 "I" 72 "H" 71 "G" 70 "F" 69 "E" 68 "D" 67 "C" 66 "B" 65 "A" 57 "9" 56 "8" 55 "7" 54 "6" 53 "5" 52 "4" 51 "3" 50 "2" 49 "1" 48 "0" ;
VAL_ 2564943859 B2V_SN_FrameNo 3 "Frame4" 2 "Frame3" 1 "Frame2" 0 "Frame1" ;
VAL_ 2550263795 B2V_RQ_VIN 1 "Request VIN" 0 "Not Request VIN" ;
VAL_ 2550330351 V2B_CMD_MainPosRelayST 3 "Invalid" 2 "Closed" 1 "Opened" 0 "Reserved" ;
VAL_ 2550330351 V2B_CMD_MainPosRelayFlt 3 "Signal Invalid" 2 "Opened Fault" 1 "Weld" 0 "Normal" ;
VAL_ 2550330351 V2B_CMD_MainNegRelayST 3 "Invalid" 2 "Closed" 1 "Opened" 0 "Reserved" ;
VAL_ 2550330351 V2B_CMD_MainNegRelayFlt 3 "Signal Invalid" 2 "Opened Fault" 1 "Weld" 0 "Normal" ;
VAL_ 2550330351 V2B_CMD_HeatPosRelayST 3 "Invalid" 2 "Closed" 1 "Opened" 0 "Reserved" ;
VAL_ 2550330351 V2B_CMD_HeatPosRelayFlt 3 "Signal Invalid" 2 "Opened Fault" 1 "Weld" 0 "Normal" ;
VAL_ 2550330351 V2B_CMD_HeatNegRelayST 3 "Invalid" 2 "Closed" 1 "Opened" 0 "Reserved" ;
VAL_ 2550330351 V2B_CMD_HeatNegRelayFlt 3 "Signal Invalid" 2 "Opened Fault" 1 "Weld" 0 "Normal" ;
VAL_ 2550330351 V2B_CMD_ChrgPosRelayST 3 "Invalid" 2 "Closed" 1 "Opened" 0 "Reserved" ;
VAL_ 2550330351 V2B_CMD_ChrgPosRelayFlt 3 "Signal Invalid" 2 "Opened Fault" 1 "Weld" 0 "Normal" ;
VAL_ 2550330351 V2B_CMD_Aux4RelayST 3 "Invalid" 2 "Closed" 1 "Opened" 0 "Reserved" ;
VAL_ 2550330351 V2B_CMD_Aux4RelayFlt 3 "Signal Invalid" 2 "Opened Fault" 1 "Weld" 0 "Normal" ;
VAL_ 2550330351 V2B_CMD_Aux3RelayST 3 "Invalid" 2 "Closed" 1 "Opened" 0 "Reserved" ;
VAL_ 2550330351 V2B_CMD_Aux3RelayFlt 3 "Signal Invalid" 2 "Opened Fault" 1 "Weld" 0 "Normal" ;
VAL_ 2550330351 V2B_CMD_Aux3OnOff 3 "Invalid" 2 "PowerOff" 1 "PowerOn" 0 "Reserved" ;
VAL_ 2550330351 V2B_CMD_Aux2RelayST 3 "Invalid" 2 "Closed" 1 "Opened" 0 "Reserved" ;
VAL_ 2550330351 V2B_CMD_Aux2RelayFlt 3 "Signal Invalid" 2 "Opened Fault" 1 "Weld" 0 "Normal" ;
VAL_ 2550330351 V2B_CMD_Aux1RelayST 3 "Invalid" 2 "Closed" 1 "Opened" 0 "Reserved" ;
VAL_ 2550330351 V2B_CMD_Aux1RelayFlt 3 "Signal Invalid" 2 "Opened Fault" 1 "Weld" 0 "Normal" ;
VAL_ 2550330351 V2B_CMD_Aux2OnOff 3 "Invalid" 2 "PowerOff" 1 "PowerOn" 0 "Reserved" ;
VAL_ 2550330351 V2B_CMD_Aux1OnOff 3 "Invalid" 2 "PowerOff" 1 "PowerOn" 0 "Reserved" ;
VAL_ 2550330351 V2B_CMD_HV_OnOff 3 "Invalid" 2 "PowerOff" 1 "PowerOn" 0 "Reserved" ;
VAL_ 2550526959 V3B_KeyonRun 1 "Stick" 0 "Normal" ;
VAL_ 2550526959 V3B_Keyon 1 "Stick" 0 "Normal" ;
VAL_ 2550526959 V2B_MainAuxPreRelayFlt 1 "Stick" 0 "Normal" ;
VAL_ 2550526959 V2B_MainAUXRelayFlt 1 "Stick" 0 "Normal" ;
VAL_ 2550526959 V2B_MainAuxPreRelayST 1 "Stick" 0 "Normal" ;
VAL_ 2550526959 V2B_MainAuxRelayST 1 "Stick" 0 "Normal" ;
VAL_ 2550526959 V2B_MainPos6RelayFlt 1 "Stick" 0 "Normal" ;
VAL_ 2550526959 V2B_MainPos5RelayFlt 1 "Stick" 0 "Normal" ;
VAL_ 2550526959 V2B_MainPos4RelayFlt 1 "Stick" 0 "Normal" ;
VAL_ 2550526959 V2B_MainPos3RelayFlt 1 "Stick" 0 "Normal" ;
VAL_ 2550526959 V2B_MainPos2RelayFlt 1 "Stick" 0 "Normal" ;
VAL_ 2550526959 V2B_MainPos1RelayFlt 1 "Stick" 0 "Normal" ;
VAL_ 2550526959 V2B_MainPosRelayFlt1 1 "Stick" 0 "Normal" ;
VAL_ 2550526959 V2B_HeatNegRelayFlt1 1 "Stick" 0 "Normal" ;
VAL_ 2550526959 V2B_HeatPosRelayFlt1 1 "Stick" 0 "Normal" ;
VAL_ 2550526959 V2B_MainNegRelayFlt1 1 "Stick" 0 "Normal" ;
VAL_ 2550526959 V7B_MainPos 1 "Close" 0 "Open" ;
VAL_ 2550526959 V6B_MainPos 1 "Close" 0 "Open" ;
VAL_ 2550526959 V5B_MainPos 1 "Close" 0 "Open" ;
VAL_ 2550526959 V4B_MainPos 1 "Close" 0 "Open" ;
VAL_ 2550526959 V3B_MainPos 1 "Close" 0 "Open" ;
VAL_ 2550526959 V2B_MainPos 1 "Close" 0 "Open" ;
VAL_ 2550526959 V2B_HeatNegRelaySt 1 "Close" 0 "Open" ;
VAL_ 2550526959 V2B_HeatPosRelaySt 1 "Close" 0 "Open" ;
VAL_ 2550526959 V2B_DCChrgNeg4RelaySt 1 "Close" 0 "Open" ;
VAL_ 2550526959 V2B_DCChrgPos4RelaySt 1 "Close" 0 "Open" ;
VAL_ 2550526959 V2B_DCChrgNeg3RelaySt 1 "Close" 0 "Open" ;
VAL_ 2550526959 V2B_DCChrgPos3RelaySt 1 "Close" 0 "Open" ;
VAL_ 2550526959 V2B_DCChrgNeg2RelaySt 1 "Close" 0 "Open" ;
VAL_ 2550526959 V2B_DCChrgPos2RelaySt 1 "Close" 0 "Open" ;
VAL_ 2550526959 V2B_DCChrgNeg1RelaySt 1 "Close" 0 "Open" ;
VAL_ 2550526959 V2B_DCChrgPos1RelaySt 1 "Close" 0 "Open" ;
VAL_ 2550526959 V2B_MainNegRelaySt 1 "Close" 0 "Open" ;
VAL_ 2559242227 B2V_InsForbidCMD 1 "allow

insulation detection" 0 "forbid insulation detection" ;
VAL_ 2559242227 B2V_MainPosRelayCMD 1 "require contactor

close" 0 "require contactor open" ;
VAL_ 2559242227 B2V_HeatNegRelayCMD 1 "require contactor

close" 0 "require contactor open" ;
VAL_ 2559242227 B2V_HeatPosRelayCMD 1 "require contactor

close" 0 "require contactor open" ;
VAL_ 2559242227 B2VChrgRelay3CMD 1 "require contactor

close" 0 "require contactor open" ;
VAL_ 2559242227 B2VChrgRelay2CMD 1 "require contactor

close" 0 "require contactor open" ;
VAL_ 2559242227 B2VChrgRelay1CMD 1 "require contactor

close" 0 "require contactor open" ;
VAL_ 2559242227 B2V_ChrgRelayCMD 1 "require contactor

close" 0 "require contactor open" ;
VAL_ 2550224627 B2V_S_ChargeControl 2 "Fault, Stop to charge" 1 "Normal Stop to charge" 0 "Start to charge" ;
VAL_ 2559111155 B2V_ST6_MinUcell_CSCNo 18 "CSC18" 17 "CSC17" 16 "CSC16" 15 "CSC15" 14 "CSC14" 13 "CSC13" 12 "CSC12" 11 "CSC11" 10 "CSC10" 9 "CSC9" 8 "CSC8" 7 "CSC7" 6 "CSC6" 5 "CSC5" 4 "CSC4" 3 "CSC3" 2 "CSC2" 1 "CSC1" ;
VAL_ 2559111155 B2V_ST6_MaxUcell_CSCNo 18 "CSC18" 17 "CSC17" 16 "CSC16" 15 "CSC15" 14 "CSC14" 13 "CSC13" 12 "CSC12" 11 "CSC11" 10 "CSC10" 9 "CSC9" 8 "CSC8" 7 "CSC7" 6 "CSC6" 5 "CSC5" 4 "CSC4" 3 "CSC3" 2 "CSC2" 1 "CSC1" ;
VAL_ 2558980083 B2V_ST4_MinTemp_CSCNo 18 "CSC18" 17 "CSC17" 16 "CSC16" 15 "CSC15" 14 "CSC14" 13 "CSC13" 12 "CSC12" 11 "CSC11" 10 "CSC10" 9 "CSC9" 8 "CSC8" 7 "CSC7" 6 "CSC6" 5 "CSC5" 4 "CSC4" 3 "CSC3" 2 "CSC2" 1 "CSC1" ;
VAL_ 2558980083 B2V_ST4_MaxTemp_CSCNo 18 "CSC18" 17 "CSC17" 16 "CSC16" 15 "CSC15" 14 "CSC14" 13 "CSC13" 12 "CSC12" 11 "CSC11" 10 "CSC10" 9 "CSC9" 8 "CSC8" 7 "CSC7" 6 "CSC6" 5 "CSC5" 4 "CSC4" 3 "CSC3" 2 "CSC2" 1 "CSC1" ;
VAL_ 2558849011 B2V_ST2_RqHVPoerOff 3 "Signal Invalid" 2 "not

require power off" 1 "require power off" 0 "Signal Invalid" ;
VAL_ 2558849011 B2V_ST2_FaultLevel 3 "Level3-Most severe fault" 2 "Level 2-

More severe fault" 1 "Level 1-Light fault" 0 "Normal" ;
VAL_ 2558717939 B2V_Fult2_ContiCurrOverLoad 3 "Level3-Most severe fault" 2 "Level 2-

More severe fault" 1 "Level 1-Light fault" 0 "Normal" ;
VAL_ 2558717939 B2V_Fult2_SOCDifferErr 1 "Fault" 0 "Norma" ;
VAL_ 2558717939 B2V_Fult2_ContiChrgCurrOverLoad 3 "Level3-Most severe fault" 2 "Level 2-

More severe fault" 1 "Level 1-Light fault" 0 "Normal" ;
VAL_ 2558717939 B2V_Fult2_FireDetectorErr 1 "Fault" 0 "Norma" ;
VAL_ 2558717939 B2V_Fult2_ELockErr 1 "Fault" 0 "Norma" ;
VAL_ 2558717939 B2V_Fult2_ChrgNTCTempOver 3 "Level3-Most severe fault" 2 "Level 2-

More severe fault" 1 "Level 1-Light fault" 0 "Normal" ;
VAL_ 2558717939 B2V_Fult2_ChrgNTCErr 1 "Fault" 0 "Norma" ;
VAL_ 2558717939 B2V_Fult2_OverChrgCurrInTheChrg 1 "Fault" 0 "Norma" ;
VAL_ 2558717939 B2V_Fult2_OverCurrWhenInCh 1 "Fault" 0 "Norma" ;
VAL_ 2558717939 B2V_Fult2_ChrgConnectErr 1 "Fault" 0 "Norma" ;
VAL_ 2558717939 B2V_Fult2_PanChrgNegRelOpEr 1 "Fault" 0 "Norma" ;
VAL_ 2558717939 B2V_Fult2_PantoChrgNegRelWeldErr 1 "Fault" 0 "Norma" ;
VAL_ 2558717939 B2V_Fult2_PantoChrgPosRelWeldErr 1 "Fault" 0 "Norma" ;
VAL_ 2558717939 B2V_Fult2_DCChrgPos4RelayOpenErr 1 "Fault" 0 "Norma" ;
VAL_ 2558717939 B2V_Fult2_DCChrgNeg3RelayWeldErr 1 "Fault" 0 "Norma" ;
VAL_ 2558717939 B2V_Fult2_DCChrgNeg3RelayOpenErr 1 "Fault" 0 "Norma" ;
VAL_ 2558717939 B2V_Fult2_DCChrgPos3RelayWeldErr 1 "Fault" 0 "Norma" ;
VAL_ 2558717939 B2V_Fult2_DCChrgPos3RelayOpenErr 1 "Fault" 0 "Norma" ;
VAL_ 2558717939 B2V_Fult2_DCChrgNeg2RelayWeldErr 1 "Fault" 0 "Norma" ;
VAL_ 2558717939 B2V_Fult2_DCChrgNeg2RelayOpenErr 1 "Fault" 0 "Norma" ;
VAL_ 2558717939 B2V_Fult2_DCChrgPos2RelayWeldErr 1 "Fault" 0 "Norma" ;
VAL_ 2558717939 B2V_Fult2_DCChrgPos2RelayOpenErr 1 "Fault" 0 "Norma" ;
VAL_ 2558717939 B2V_Fult2_DCChrgNeg1RelayWeldErr 1 "Fault" 0 "Norma" ;
VAL_ 2558717939 B2V_Fult2_DCChrgNeg1RelayOpenErr 1 "Fault" 0 "Norma" ;
VAL_ 2558717939 B2V_Fult2_DCChrgPos1RelayWeldErr 1 "Fault" 0 "Norma" ;
VAL_ 2558717939 B2V_Fult2_DCChrgPos1RelayOpenErr 1 "Fault" 0 "Norma" ;
VAL_ 2558717939 B2V_Fult2_MainNegRelayWeldErr 1 "Fault" 0 "Norma" ;
VAL_ 2558717939 B2V_Fult2_MainNegRelayOpenErr 1 "Fault" 0 "Norma" ;
VAL_ 2558717939 B2V_Fult2_MainPosRelayWeldErr 1 "Fault" 0 "Norma" ;
VAL_ 2558717939 B2V_Fult2_MainPosRelayOpenErr 1 "Fault" 0 "Norma" ;
VAL_ 2558717939 B2V_Fult2_HeatRelayWeldErr 1 "Fault" 0 "Norma" ;
VAL_ 2558717939 B2V_Fult2_HeatRelayOpenErr 1 "Fault" 0 "Norma" ;
VAL_ 2558717939 B2V_Fult2_BranchBreakErr 1 "Fault" 0 "Norma" ;
VAL_ 2558717939 B2V_Fult2_DCDCErr 1 "Fault" 0 "Norma" ;
VAL_ 2558717939 B2V_Fult2_InnerCommunicationErr 1 "Fault" 0 "Norma" ;
VAL_ 2558717939 B2V_Fult2_ACANLost 1 "Fault" 0 "Normal" ;
VAL_ 2558717939 B2V_Fult2_ChrgInsLowErr 1 "Fault" 0 "Norma" ;
VAL_ 2558717939 B2V_Fult2_AuxLoopPrechrgErr 1 "Fault" 0 "Norma" ;
VAL_ 2558717939 B2V_Fult2_MainLoopPrechrgErr 1 "Fault" 0 "Norma" ;
VAL_ 2558717939 B2V_Fult2_PackSelfProtect 1 "Fault" 0 "Norma" ;
VAL_ 2558717939 B2V_Fult2_HeatungFilmErr 1 "Fault" 0 "Norma" ;
VAL_ 2558717939 B2V_Fult2_TMSErr 1 "Fault" 0 "Norma" ;
VAL_ 2558717939 B2V_Fult2_PowerSupplyErr 1 "Fault" 0 "Norma" ;
VAL_ 2558717939 B2V_Fult2_CurrSensorErr 1 "Fault" 0 "Norma" ;
VAL_ 2558717939 B2V_Fult2_OverChrgCurrInTheDrive 3 "Level3-Most severe fault" 2 "Level 2-

More severe fault" 1 "Level 1-Light fault" 0 "Normal" ;
VAL_ 2558717939 B2V_Fult2_OverDischrgCurr 3 "Level3-Most severe fault" 2 "Level 2-

More severe fault" 1 "Level 1-Light fault" 0 "Normal" ;
VAL_ 2558717939 B2V_Fult2_PackFireWarning 1 "Fault" 0 "Norma" ;
VAL_ 2558717939 B2V_Fult2_CellLowTemp 1 "Fault" 0 "Norma" ;
VAL_ 2558717939 B2V_Fult2_CellOverDischrg 1 "Fault" 0 "Norma" ;
VAL_ 2565009395 B2V_BI1_BattManufacture 7 "Others" 6 "SUNWODA" 5 "GUOXUAN HIGH_TECH" 4 "LG" 3 "SAMSUN" 2 "MGL" 1 "Li Shen" 0 "CATL" ;
VAL_ 2565009395 B2V_BI1_CoolType 3 "Water cooling" 2 "Fan cooling" 1 "Natural cooling" 0 "Other cooling mode" ;
VAL_ 2565009395 B2V_BI1_BattType 14 "其他车载储能装置" 13 "燃

料电池 Fuel battery" 12 "Reserved" 11 "Reserved" 10 "Reserved" 9 "Reserved" 8 "超级电容Super-capaciyor" 7 "钛酸锂电池" 6 "聚合物锂离子电池" 5 "三元材料电池 NCM" 4 "钴酸锂电池" 3 "锰酸锂电池" 2 "磷酸铁锂电池LEP" 1 "镍氢电池NIMH Battery" 0 "铅酸电池Lead-acid battery" ;
VAL_ 2564944879 V2B_VIN_B7_14 90 "Z" 89 "Y" 88 "X" 87 "W" 86 "V" 85 "U" 84 "T" 83 "S" 82 "R" 81 "Q" 80 "P" 79 "O" 78 "N" 77 "M" 76 "L" 75 "K" 74 "J" 73 "I" 72 "H" 71 "G" 70 "F" 69 "E" 68 "D" 67 "C" 66 "B" 65 "A" 57 "9" 56 "8" 55 "7" 54 "6" 53 "5" 52 "4" 51 "3" 50 "2" 49 "1" 48 "0" ;
VAL_ 2564944879 V2B_VIN_B6_13 90 "Z" 89 "Y" 88 "X" 87 "W" 86 "V" 85 "U" 84 "T" 83 "S" 82 "R" 81 "Q" 80 "P" 79 "O" 78 "N" 77 "M" 76 "L" 75 "K" 74 "J" 73 "I" 72 "H" 71 "G" 70 "F" 69 "E" 68 "D" 67 "C" 66 "B" 65 "A" 57 "9" 56 "8" 55 "7" 54 "6" 53 "5" 52 "4" 51 "3" 50 "2" 49 "1" 48 "0" ;
VAL_ 2564944879 V2B_VIN_B5_12 90 "Z" 89 "Y" 88 "X" 87 "W" 86 "V" 85 "U" 84 "T" 83 "S" 82 "R" 81 "Q" 80 "P" 79 "O" 78 "N" 77 "M" 76 "L" 75 "K" 74 "J" 73 "I" 72 "H" 71 "G" 70 "F" 69 "E" 68 "D" 67 "C" 66 "B" 65 "A" 57 "9" 56 "8" 55 "7" 54 "6" 53 "5" 52 "4" 51 "3" 50 "2" 49 "1" 48 "0" ;
VAL_ 2564944879 V2B_VIN_B4_11 90 "Z" 89 "Y" 88 "X" 87 "W" 86 "V" 85 "U" 84 "T" 83 "S" 82 "R" 81 "Q" 80 "P" 79 "O" 78 "N" 77 "M" 76 "L" 75 "K" 74 "J" 73 "I" 72 "H" 71 "G" 70 "F" 69 "E" 68 "D" 67 "C" 66 "B" 65 "A" 57 "9" 56 "8" 55 "7" 54 "6" 53 "5" 52 "4" 51 "3" 50 "2" 49 "1" 48 "0" ;
VAL_ 2564944879 V2B_VIN_B3_10_17 90 "Z" 89 "Y" 88 "X" 87 "W" 86 "V" 85 "U" 84 "T" 83 "S" 82 "R" 81 "Q" 80 "P" 79 "O" 78 "N" 77 "M" 76 "L" 75 "K" 74 "J" 73 "I" 72 "H" 71 "G" 70 "F" 69 "E" 68 "D" 67 "C" 66 "B" 65 "A" 57 "9" 56 "8" 55 "7" 54 "6" 53 "5" 52 "4" 51 "3" 50 "2" 49 "1" 48 "0" ;
VAL_ 2564944879 V2B_VIN_B2_9_16 90 "Z" 89 "Y" 88 "X" 87 "W" 86 "V" 85 "U" 84 "T" 83 "S" 82 "R" 81 "Q" 80 "P" 79 "O" 78 "N" 77 "M" 76 "L" 75 "K" 74 "J" 73 "I" 72 "H" 71 "G" 70 "F" 69 "E" 68 "D" 67 "C" 66 "B" 65 "A" 57 "9" 56 "8" 55 "7" 54 "6" 53 "5" 52 "4" 51 "3" 50 "2" 49 "1" 48 "0" ;
VAL_ 2564944879 V2B_VIN_B1_8_15 90 "Z" 89 "Y" 88 "X" 87 "W" 86 "V" 85 "U" 84 "T" 83 "S" 82 "R" 81 "Q" 80 "P" 79 "O" 78 "N" 77 "M" 76 "L" 75 "K" 74 "J" 73 "I" 72 "H" 71 "G" 70 "F" 69 "E" 68 "D" 67 "C" 66 "B" 65 "A" 57 "9" 56 "8" 55 "7" 54 "6" 53 "5" 52 "4" 51 "3" 50 "2" 49 "1" 48 "0" ;
VAL_ 2550395887 ISOWorkStatus 3 "equipment failure" 2 "stop work" 1 "working" 0 "Selfcheck" ;
VAL_ 2550395887 ISO_FaultLevel 3 "Level3-Most severe fault" 2 "Level 2-

More severe fault" 1 "Level 1-Light fault" 0 "Normal" ;
